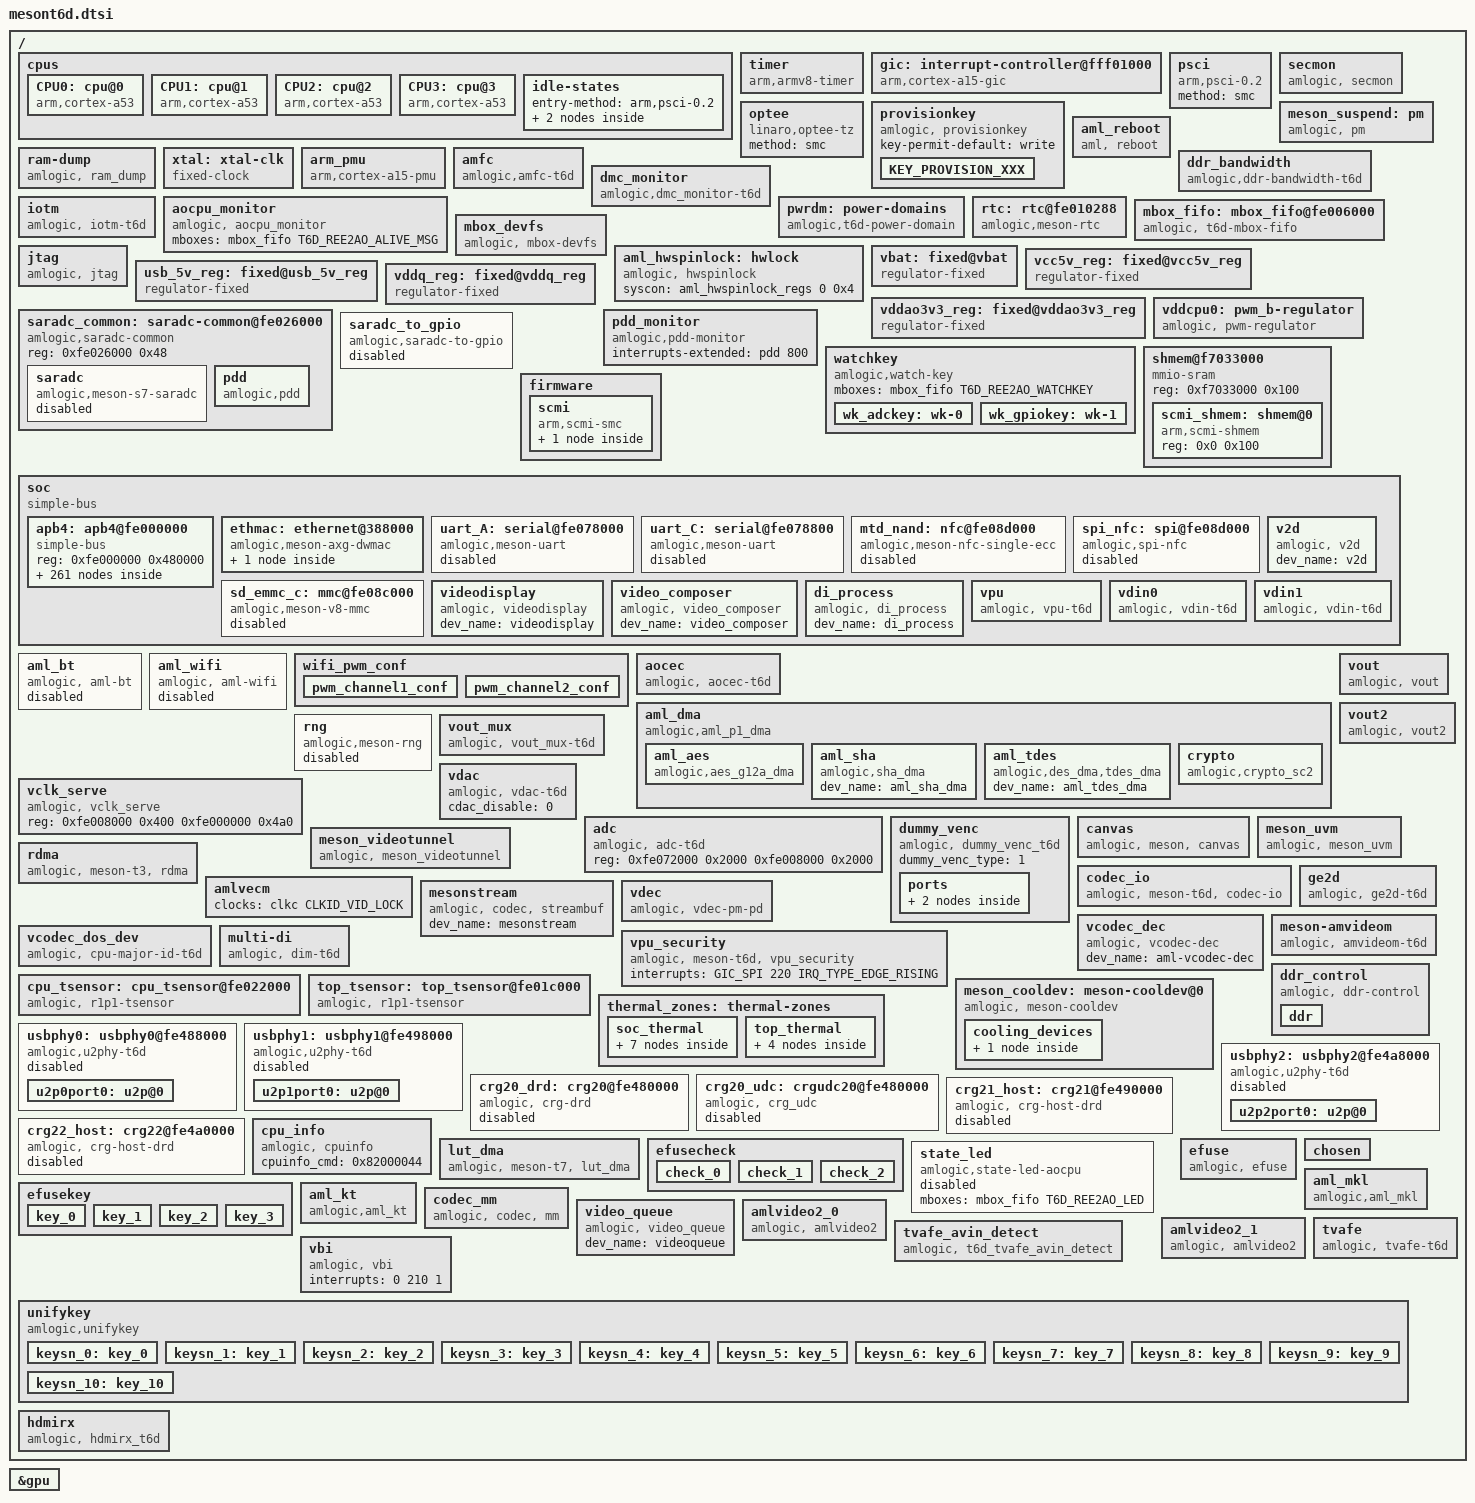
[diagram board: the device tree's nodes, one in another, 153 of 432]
// SPDX-License-Identifier: (GPL-2.0+ OR MIT)
/*
 * Copyright (c) 2021 Amlogic, Inc. All rights reserved.
 */

#include <dt-bindings/interrupt-controller/irq.h>
#include <dt-bindings/interrupt-controller/arm-gic.h>
#include <dt-bindings/reset/amlogic,meson-t6d-reset.h>
#include <dt-bindings/clock/t6d-clkc.h>
#include <dt-bindings/clock/t6d-scmi-clkc.h>
#include <dt-bindings/gpio/gpio.h>
#include <dt-bindings/gpio/meson-t6d-gpio.h>
#include <dt-bindings/power/t6d-pd.h>
#include <dt-bindings/pwm/pwm.h>
#include <dt-bindings/pwm/meson.h>
#include <dt-bindings/input/input.h>
#include <dt-bindings/input/meson_ir.h>
#include <dt-bindings/iio/adc/amlogic-saradc.h>
#include "meson-ir-map.dtsi"
#include "mesong12a-bifrost.dtsi"
#include <dt-bindings/mailbox/t6d-mbox.h>
#include <dt-bindings/thermal/thermal.h>
#include <dt-bindings/thermal/ddr-params.h>
#include <dt-bindings/hwspinlock/amlogic,hwspinlock.h>
#include <dt-bindings/leds/leds-meson.h>

/ {
	cpus:cpus {
		#address-cells = <1>;
		#size-cells = <0>;

		CPU0:cpu@0 {
			device_type = "cpu";
			compatible = "arm,cortex-a53","arm,armv8";
			reg = <0x0>;
			enable-method = "psci";
			cpu-idle-states = <&CPU_SLEEP_0 &SYSTEM_SLEEP_0>;
			dynamic-power-coefficient = <230>;
			#cooling-cells = <2>;
		};

		CPU1:cpu@1{
			device_type = "cpu";
			compatible = "arm,cortex-a53","arm,armv8";
			reg = <0x1>;
			enable-method = "psci";
			cpu-idle-states = <&CPU_SLEEP_0 &SYSTEM_SLEEP_0>;
			dynamic-power-coefficient = <230>;
			#cooling-cells = <2>;
		};

		CPU2:cpu@2 {
			device_type = "cpu";
			compatible = "arm,cortex-a53","arm,armv8";
			reg = <0x2>;
			enable-method = "psci";
			cpu-idle-states = <&CPU_SLEEP_0 &SYSTEM_SLEEP_0>;
			dynamic-power-coefficient = <230>;
			#cooling-cells = <2>;
		};

		CPU3:cpu@3 {
			device_type = "cpu";
			compatible = "arm,cortex-a53","arm,armv8";
			reg = <0x3>;
			enable-method = "psci";
			cpu-idle-states = <&CPU_SLEEP_0 &SYSTEM_SLEEP_0>;
			dynamic-power-coefficient = <230>;
			#cooling-cells = <2>;
		};

		idle-states {
			entry-method = "arm,psci-0.2";
			CPU_SLEEP_0: cpu-sleep-0 {
					compatible = "arm,idle-state";
					arm,psci-suspend-param = <0x0010000>;
					local-timer-stop;
					entry-latency-us = <600>;
					exit-latency-us = <630>;
					min-residency-us = <6140>;
			};
			SYSTEM_SLEEP_0: system-sleep-0 {
					compatible = "arm,idle-state";
					arm,psci-suspend-param = <0x0000000>;
					entry-latency-us = <0x3fffffff>;
					exit-latency-us = <0x40000000>;
					min-residency-us = <0xffffffff>;
			};
		};
	};

	timer {
		compatible = "arm,armv8-timer";
		interrupts = <GIC_PPI 13 0xff08>,
				<GIC_PPI 14 0xff08>,
				<GIC_PPI 11 0xff08>,
				<GIC_PPI 10 0xff08>;
	};

	gic: interrupt-controller@fff01000 {
		compatible = "arm,cortex-a15-gic", "arm,cortex-a9-gic";
		#interrupt-cells = <3>;
		#address-cells = <0>;
		interrupt-controller;
		reg = <0xfff01000 0x1000>,
		      <0xfff02000 0x0100>;
		interrupts = <GIC_PPI 9 0xf04>;
	};

	psci {
		compatible = "arm,psci-0.2";
		method = "smc";
	};

	secmon {
		compatible = "amlogic, secmon";
		memory-region = <&secmon_reserved>;
		in_base_func = <0x82000020>;
		out_base_func = <0x82000021>;
		inout_size_func = <0x8200002a>;
		reserve_mem_size = <0x01300000>;
	};

	optee {
		compatible = "linaro,optee-tz";
		method = "smc";
	};

	provisionkey {
		compatible = "amlogic, provisionkey";
		status = "okay";
		key-permit-default = "write";
		//new key not need add dts if started with KEY_PROVISION_
		KEY_PROVISION_XXX { };
		//test_my_added_keyname { };
	};//End provisionkey

	provisionkey {
		compatible = "amlogic, provisionkey";
		status = "okay";
		key-permit-default = "write";
		//new key not need add dts if started with KEY_PROVISION_
		KEY_PROVISION_XXX { };
		//test_my_added_keyname { };
	};//End provisionkey

	meson_suspend:pm {
		compatible = "amlogic, pm";
		device_name = "aml_pm";
		extend_resume_reason;
		reg = <0xfe010288 0x4>, /*SYSCTRL_STATUS_REG2*/
			<0xfe0102dc 0x4>; /*SYSCTRL_STICKY_REG7*/
		status = "okay";
	};

	aml_reboot {
		compatible = "aml, reboot";
		sys_reset = <0x84000009>;
		sys_poweroff = <0x84000008>;
		dis_nb_cpus_in_shutdown;
		extend_reboot_reason; /* Support up to 128 reboot reasons*/
		reg = <0xfe01037c 0x4>; /* SEC_AO_SEC_SD_CFG15 */
		status = "okay";
	};

	ram-dump {
		compatible = "amlogic, ram_dump";
		status = "okay";
		reg = <0xFE0102D8 4>;
		reg-names = "SYSCTRL_STICKY_REG6";
		store_device = "data";
	};

	xtal: xtal-clk {
		compatible = "fixed-clock";
		clock-frequency = <24000000>;
		clock-output-names = "xtal";
		#clock-cells = <0>;
	};

	arm_pmu {
		compatible = "arm,cortex-a15-pmu";
		private-interrupts;
		interrupts = <GIC_SPI 233 IRQ_TYPE_LEVEL_HIGH>,
				<GIC_SPI 234 IRQ_TYPE_LEVEL_HIGH>,
				<GIC_SPI 235 IRQ_TYPE_LEVEL_HIGH>,
				<GIC_SPI 236 IRQ_TYPE_LEVEL_HIGH>;
	};

	amfc {
		compatible = "amlogic,amfc-t6d";
		status = "okay";
		/* registers and clk, efuse license */
		reg = <0xfe092000 0x200
		       0xFDFFFF6C 0x400
		       0xfe440048 0x400>;
		interrupts = <0 221 IRQ_TYPE_EDGE_RISING
			      0 222 IRQ_TYPE_EDGE_RISING>;
		power-domains = <&pwrdm PDID_T6D_AMFC>;
		interrupt-names = "amfc0", "amfc1";
		clocks = <&clkc CLKID_AMFC>;
		assigned-clocks = <&clkc CLKID_AMFC>;
		assigned-clock-rates = <576000000>;
	};

	ddr_bandwidth {
		compatible = "amlogic,ddr-bandwidth-t6d";
		status = "okay";
		reg = <0xfe036000 0x1000
		       0xfe0368a8 0x4>;
		bus_width_reg = <0xfe036814>;
		interrupts = <0 136 IRQ_TYPE_EDGE_RISING>;
		interrupt-names = "ddr_bandwidth";
	};

	dmc_monitor {
		compatible = "amlogic,dmc_monitor-t6d";
		status = "okay";
		memory-region = <&dmc_reserved>;
		reg = <0xfe036000 0x400>;
		reg_base = <0xfe036000>;
		interrupts = <0 137 IRQ_TYPE_LEVEL_HIGH
			      0 139 IRQ_TYPE_EDGE_RISING>;
	};

	iotm {
		compatible = "amlogic, iotm-t6d";
		status = "okay";
		/* a53_dbg: CSSYS_BASE_ADDR + iotm & coresight */
		reg = <0xfe800000 0x8000>;/* a53_debug */
		exclude-reg = <0xfe807044 0xfe807048>, /* software_write_record of a53_debug */
			      <0xfe078000 0xfe07a000>, /* uart(a-d) */
			      <0xff8100e4 0xff8100e8>, /* vpu amvecm */
			      <0xfe092000 0xfe094000>; /* amfc */
		memory-region = <&debug_reserved>;
		interrupts = <GIC_SPI 128 IRQ_TYPE_LEVEL_HIGH>;
		version = <1>;
	};

	aocpu_monitor {
		compatible = "amlogic, aocpu_monitor";
		status = "okay";
		mboxes = <&mbox_fifo T6D_REE2AO_ALIVE_MSG>;
	};

	pwrdm: power-domains {
		compatible = "amlogic,t6d-power-domain";
		#power-domain-cells = <1>;
		status = "okay";
	};

	rtc: rtc@fe010288 {
		compatible = "amlogic,meson-rtc";
		reg = <0xfe010288 0x4>; //SYSCTRL_STATUS_REG2
		interrupts = <GIC_SPI 3 IRQ_TYPE_EDGE_RISING>;
		status = "okay";
		mboxes = <&mbox_fifo T6D_REE2AO_VRTC>;
		rtc-virtual;
	};

	mbox_fifo: mbox_fifo@fe006000 {
		status = "okay";
		compatible = "amlogic, t6d-mbox-fifo";
		reg = <0xfe006000 0x800>,  /* mbox wr fifo */
		      <0xfe007180 0x80>,   /* mbox set reg */
		      <0xfe007200 0x80>,   /* mbox clr reg */
		      <0xfe007280 0x80>,   /* mbox sts reg */
		      <0xfe007040 0xc0>;   /* mbox irqctrl reg */
		interrupts = <GIC_SPI 248 IRQ_TYPE_EDGE_RISING>;  /* mbox irq top */
		mbox-irqmax = <32>;
		mbox-irqctlr = <0x14>;
		mbox-irqclr = <0x8>;
		mbox-nums = <T6D_MBOX_NUMS>;
		mboxids = <T6D_MBOX_AO2REE>,
			  <T6D_MBOX_REE2AO>;
		#mbox-cells = <1>;
		mbox-wr-same;
		mbox-dests = <MAILBOX_ARM>,
			     <MAILBOX_AOCPU>;
		aocpu-hang-detect;
		aocpu-sts-mboxid = <T6D_AOCPU_STS_CHAN>;
	};

	mbox_devfs {
		status = "okay";
		compatible = "amlogic, mbox-devfs";
		mbox-nums = <2>;
		mbox-names = "ree2aocpu",
			  "aocpu2ree";
		mboxes = <&mbox_fifo T6D_REE2AO_DEV>,
			  <&mbox_fifo T6D_AO2REE_DEV>;
	};

	aml_hwspinlock: hwlock {
		status = "okay";
		compatible = "amlogic, hwspinlock";
		syscon = <&aml_hwspinlock_regs 0 0x4>;
		#hwlock-cells = <1>;
	};

	jtag {
		compatible = "amlogic, jtag";
		status = "okay";
		select = "disable"; /* disable/jtag_a/jtag_b */
		pinctrl-names="jtag_a_pins", "jtag_b_pins";
		pinctrl-0=<&jtag_a_pins>;
		pinctrl-1=<&jtag_b_pins>;
	};

	vbat: fixed@vbat {
		compatible = "regulator-fixed";
		regulator-name = "12V";
		regulator-min-microvolt = <12000000>;
		regulator-max-microvolt = <12000000>;
		regulator-boot-on;
		regulator-always-on;
	};

	vcc5v_reg: fixed@vcc5v_reg {
		vin-supply = <&vbat>;
		compatible = "regulator-fixed";
		regulator-name = "5V/VCC_5V";
		regulator-min-microvolt = <5000000>;
		regulator-max-microvolt = <5000000>;
		gpio = <&gpio GPIO_TEST_N GPIO_ACTIVE_HIGH>;
		startup-delay-us = <7000>;
		enable-active-high;
		regulator-boot-on;
		regulator-always-on;
	};

	usb_5v_reg: fixed@usb_5v_reg {
		compatible = "regulator-fixed";
		vin-supply = <&vcc5v_reg>;
		regulator-name = "USB_5V/OTG_VCC5V,USBBC_PWR";
		regulator-min-microvolt = <5000000>;
		regulator-max-microvolt = <5000000>;
		regulator-boot-on;
		regulator-always-on;
	};

	vddq_reg: fixed@vddq_reg {
		compatible = "regulator-fixed";
		vin-supply = <&vbat>;
		regulator-name = "VDDQ";
		regulator-min-microvolt = <1220000>;
		regulator-max-microvolt = <1220000>;
		pinctrl-names = "default";
		gpio = <&gpio GPIOD_4 GPIO_ACTIVE_HIGH>;
		startup-delay-us = <7000>;
		enable-active-high;
		regulator-boot-on;
		regulator-always-on;
	};

	vddao3v3_reg: fixed@vddao3v3_reg {
		vin-supply = <&vbat>;
		compatible = "regulator-fixed";
		regulator-name = "VDDAO_3.3V";
		regulator-min-microvolt = <3300000>;
		regulator-max-microvolt = <3300000>;
		regulator-boot-on;
		regulator-always-on;
	};

	vddcpu0: pwm_b-regulator {
		compatible = "amlogic, pwm-regulator";
		pwms = <&pwm_b MESON_PWM_0 1512 0>;
		regulator-name = "vddcpu0";
		regulator-min-microvolt = <689000>;
		regulator-max-microvolt = <1049000>;
		regulator-always-on;
		max-duty-cycle = <1512>;
		amlogic,vsel-step = <3>;
		amlogic,usleep-time = <200>;
		/* Voltage Duty-Cycle */
		voltage-table = <1049000 0>,
				<1039000 3>,
				<1029000 6>,
				<1019000 8>,
				<1009000 11>,
				<999000 14>,
				<989000 17>,
				<979000 19>,
				<969000 22>,
				<959000 25>,
				<949000 28>,
				<939000 31>,
				<929000 33>,
				<919000 36>,
				<909000 39>,
				<899000 42>,
				<889000 44>,
				<879000 47>,
				<869000 50>,
				<859000 53>,
				<849000 56>,
				<839000 58>,
				<829000 61>,
				<819000 64>,
				<809000 67>,
				<799000 69>,
				<789000 72>,
				<779000 75>,
				<769000 78>,
				<759000 81>,
				<749000 83>,
				<739000 86>,
				<729000 89>,
				<719000 92>,
				<709000 94>,
				<699000 97>,
				<689000 100>;
		status = "okay";
	};

	saradc_common: saradc-common@fe026000 {
		compatible = "amlogic,saradc-common";
		reg = <0xfe026000 0x48>;

		saradc: saradc {
			compatible = "amlogic,meson-s7-saradc",
				     "amlogic,meson-saradc";
			status = "disabled";
			#io-channel-cells = <1>;
			clocks = <&xtal>,
				 <&clkc CLKID_SYS_SARADC>,
				 <&clkc CLKID_SARADC>,
				 <&clkc CLKID_SARADC_SEL>;
			clock-names = "clkin", "core", "adc_clk", "adc_sel";
			interrupts = <GIC_SPI 181 IRQ_TYPE_EDGE_RISING>;
			watch-key = <&wk_adckey>;
		};

		pdd: pdd {
			compatible = "amlogic,pdd";
			interrupt-controller;
			#interrupt-cells = <1>;
			clock-names = "core";
			clocks = <&clkc CLKID_SYS_SARADC>;
			amlogic,interrupt = <182>;
			amlogic,digital-maps = <0x2c 26>, <0x2c 25>, <0x2c 24>,
					       <0x2c 19>, <0x2c 16>;
			amlogic,analog-maps = <0x2c 9>, <0x2c 3>, <0x2c 1>;
			amlogic,voltage-maps = <400>, <800>, <800>, <1200>;
			status = "okay";
		};
	};

	pdd_monitor {
		compatible = "amlogic,pdd-monitor";
		/* Trigger threshold voltage: 800 mV */
		interrupts-extended = <&pdd 800>;
		status = "okay";
	};

	saradc_to_gpio {
		compatible = "amlogic,saradc-to-gpio";
		io-channels = <&saradc SARADC_CH0>, <&saradc SARADC_CH1>,
			      <&saradc SARADC_CH2>, <&saradc SARADC_CH3>,
			      <&saradc SARADC_CH4>, <&saradc SARADC_CH5>,
			      <&saradc SARADC_CH6>, <&saradc SARADC_CH7>;
		amlogic,threshold = <900 900 900 900 900 900 900 900>;
		status = "disabled";
	};

	watchkey: watchkey {
		compatible = "amlogic,watch-key";
		mboxes = <&mbox_fifo T6D_REE2AO_WATCHKEY>;

		wk_adckey: wk-0 {
			wk-name = "adc-keypad";
			wk-id = <0>;
			wk-type = <EV_KEY>;
			wk-code = <KEY_POWER>;
			/* wk-report-event; */
		};

		wk_gpiokey: wk-1 {
			wk-name = "gpio-keypad";
			wk-id = <1>;
			wk-type = <EV_KEY>;
			wk-code = <KEY_POWER>;
			/* wk-report-event; */
		};
	};

	shmem@f7033000 {
		compatible = "mmio-sram";
		reg = <0xf7033000 0x100>;
		#address-cells = <1>;
		#size-cells = <1>;
		ranges = <0x0 0xf7033000 0x100>;

		scmi_shmem: shmem@0 {
			compatible = "arm,scmi-shmem";
			reg = <0x0 0x100>;
		};
	};

	firmware {
		scmi: scmi {
			compatible = "arm,scmi-smc";
			arm,smc-id = <0x820000c1>;
			shmem = <&scmi_shmem>;
			#address-cells = <1>;
			#size-cells = <0>;

			scmi_clk: protocol@14 {
				reg = <0x14>;
				#clock-cells = <1>;
			};
		};
	};

	soc {
		compatible = "simple-bus";
		#address-cells = <1>;
		#size-cells = <1>;
		ranges;

		apb4: apb4@fe000000 {
			compatible = "simple-bus";
			reg = <0xfe000000 0x480000>;
			#address-cells = <1>;
			#size-cells = <1>;
			ranges = <0x0 0xfe000000 0x480000>;

			reset: reset-controller@2000 {
				compatible = "amlogic,meson-t5m-reset";
				reg = <0x2000 0x98>;
				#reset-cells = <1>;
			};

			watchdog@2100 {
				compatible = "amlogic,meson-a4-wdt";
				status = "okay";
				/* 0:userspace, 1:kernel */
				amlogic,feed_watchdog_mode = <1>;
				reg = <0x2100 0x10>,
				      <0x226c 0x04>;
				interrupts = <GIC_SPI 9 IRQ_TYPE_EDGE_RISING>;
				clocks = <&xtal>;
			};

			clkc: clock-controller {
				compatible = "amlogic,t6d-clkc";
				#clock-cells = <1>;
				reg = <0x0 0x244>,
				      <0x8000 0xe0>;
				reg-names = "basic", "pll";
				clocks = <&xtal>;
				clock-names = "xtal";
				gp0-spread-spectrum = <0>; /* 500,1000,1500...*/
				status = "okay";
			};

			meson_clk_msr@48000 {
				compatible = "amlogic,meson-t6d-clk-measure";
				reg = <0x48000 0x1c>;
				status = "okay";
			};

			uart_B: serial@78400 {
				compatible = "amlogic,meson-uart";
				reg = <0x78400 0x18>;
				interrupts = <0 169 1>;
				status = "disabled";
				clocks = <&xtal>;
				clock-names = "clk_uart";
				xtal_tick_en = <2>;
				fifosize = < 64 >;
				/* 0 not support; 1 support */
				support-sysrq = <1>;
			};

			periphs_pinctrl: pinctrl@4000 {
				compatible = "amlogic,meson-t6d-periphs-pinctrl";
				#address-cells = <1>;
				#size-cells = <1>;
				ranges;

				gpio: bank@4000 {
					reg = <0x4000 0x0058>,
					      <0x40c0 0x030c>;
					reg-names = "mux", "gpio";
					gpio-controller;
					#gpio-cells = <2>;
					gpio-ranges = <&periphs_pinctrl 0 0 129>;
				};
			};

			gpio_intc: interrupt-controller@4080 {
				compatible = "amlogic,meson-t6d-gpio-intc",
					     "amlogic,meson-gpio-intc";
				reg = <0x4080 0x20>;
				interrupt-controller;
				#interrupt-cells = <2>;
				amlogic,channel-interrupts =
					<10 11 12 13 14 15 16 17 18 19 20 21>;
			};

			pinctrl_analog: pinctrl@43cc {
				compatible = "amlogic,meson-t6d-analog-pinctrl";
				#address-cells = <1>;
				#size-cells = <1>;
				ranges;

				gpio_analog: analog-bank@43cc {
					reg = <0x43d4 0x0004>,
					      <0x43cc 0x0008>;
					reg-names = "mux", "gpio";
					gpio-controller;
					#gpio-cells = <2>;
					gpio-ranges = <&pinctrl_analog 0 0 2>;
				};
			};

			spicc0: spi@50000 {
				compatible = "amlogic,meson-a4-spicc-v2";
				reg = <0x50000 0x38>;
				interrupts = <GIC_SPI 183 IRQ_TYPE_LEVEL_HIGH>;
				clocks = <&clkc CLKID_SYS_SPISG>,
					 <&clkc CLKID_SPICC0>;
				clock-names = "sys", "spi";
				#address-cells = <1>;
				#size-cells = <0>;
				status = "disabled";
			};

			spicc1: spi@50100 {
				compatible = "amlogic,meson-a4-spicc-v2";
				reg = <0x50100 0x38>;
				interrupts = <GIC_SPI 184 IRQ_TYPE_LEVEL_HIGH>;
				clocks = <&clkc CLKID_SYS_SPISG>,
					 <&clkc CLKID_SPICC1>;
				clock-names = "sys", "spi";
				#address-cells = <1>;
				#size-cells = <0>;
				status = "disabled";
			};

			pwm_a: pwm@58000 {
				compatible = "amlogic,meson-even-pwm";
				reg = <0x58000 0x24>,
					  <0x180 0x4>;
				#pwm-cells = <3>;
				clocks = <&clkc CLKID_PWM_A_SEL>;
				clock-names = "clkin0";
				status = "disabled";
			};

			pwm_b: pwm@58200 {
				compatible = "amlogic,meson-pwm-tee";
				reg = <0x58200 0x24>;
				#pwm-cells = <3>;
				clocks = <&clkc CLKID_PWM_B>;
				clock-names = "clkin0";
				tee_id = <1>;
				status = "okay";
			};

			pwm_c: pwm@58400 {
				compatible = "amlogic,meson-even-pwm";
				reg = <0x58400 0x24>,
					  <0x184 0x4>;
				#pwm-cells = <3>;
				clocks = <&clkc CLKID_PWM_C_SEL>;
				clock-names = "clkin0";
				status = "disabled";
			};

			pwm_d: pwm@58600 {
				compatible = "amlogic,meson-odd-pwm";
				reg = <0x58600 0x24>,
					  <0x184 0x4>;
				#pwm-cells = <3>;
				clocks = <&clkc CLKID_PWM_D_SEL>;
				clock-names = "clkin0";
				status = "disabled";
			};

			pwm_e: pwm@58800 {
				compatible = "amlogic,meson-even-pwm";
				reg = <0x58800 0x24>,
					  <0x188 0x4>;
				#pwm-cells = <3>;
				clocks = <&clkc CLKID_PWM_E_SEL>;
				clock-names = "clkin0";
				status = "disabled";
			};

			pwm_f: pwm@58a00 {
				compatible = "amlogic,meson-odd-pwm";
				reg = <0x58a00 0x24>,
					  <0x188 0x4>;
				#pwm-cells = <3>;
				clocks = <&clkc CLKID_PWM_F_SEL>;
				clock-names = "clkin0";
				status = "disabled";
			};

			pwm_g: pwm@58c00 {
				compatible = "amlogic,meson-even-pwm";
				reg = <0x58c00 0x24>,
					  <0x18c 0x4>;
				#pwm-cells = <3>;
				clocks = <&clkc CLKID_PWM_G_SEL>;
				clock-names = "clkin0";
				status = "disabled";
			};

			pwm_h: pwm@58e00 {
				compatible = "amlogic,meson-odd-pwm";
				reg = <0x58e00 0x24>,
					  <0x18c 0x4>;
				#pwm-cells = <3>;
				clocks = <&clkc CLKID_PWM_H_SEL>;
				clock-names = "clkin0";
				status = "disabled";
			};

			i2c0: i2c@66000 {
				compatible = "amlogic,meson-i2c";
				reg = <0x66000 0x28>;
				interrupts = <GIC_SPI 160 IRQ_TYPE_EDGE_RISING>;
				#address-cells = <1>;
				#size-cells = <0>;
				clocks = <&clkc CLKID_SYS_I2C_M_WRAPPER>;
				status = "disabled";
			};

			i2c1: i2c@66400 {
				compatible = "amlogic,meson-i2c";
				reg = <0x66400 0x28>;
				interrupts = <GIC_SPI 161 IRQ_TYPE_EDGE_RISING>;
				#address-cells = <1>;
				#size-cells = <0>;
				clocks = <&clkc CLKID_SYS_I2C_M_WRAPPER>;
				status = "disabled";
			};

			i2c2: i2c@66800 {
				compatible = "amlogic,meson-i2c";
				reg = <0x66800 0x28>;
				interrupts = <GIC_SPI 162 IRQ_TYPE_EDGE_RISING>;
				#address-cells = <1>;
				#size-cells = <0>;
				clocks = <&clkc CLKID_SYS_I2C_M_WRAPPER>;
				status = "disabled";
			};

			i2c3: i2c@66c00 {
				compatible = "amlogic,meson-i2c";
				reg = <0x66c00 0x28>;
				interrupts = <GIC_SPI 163 IRQ_TYPE_EDGE_RISING>;
				#address-cells = <1>;
				#size-cells = <0>;
				clocks = <&clkc CLKID_SYS_I2C_M_WRAPPER>;
				status = "disabled";
			};

			dcon_led: dcon_led@74000 {
				compatible = "amlogic,led_unipolar_ctrl";
				reg = <0x74000 0x88>;
				interrupts = <GIC_SPI 30 IRQ_TYPE_EDGE_RISING>;
				led-mode = <LED_MESON_RGB>;
				led_number = <2>;
				status = "disabled";
			};

			ir: ir@fe084000 {
				compatible = "amlogic, meson-ir";
				reg = <0x84080 0xA4>,
					<0x84000 0x58>;
				status = "disabled";
				protocol = <REMOTE_TYPE_NEC>;
				interrupts = <GIC_SPI 22 IRQ_TYPE_EDGE_RISING>;
				map = <&custom_maps>;
				wakeup_map = <&ir_wakeup_key>;
				mboxes = <&mbox_fifo T6D_REE2AO_IR>;
				max_frame_time = <200>;
			};

			ir1: ir1@fe084180 {
				compatible = "amlogic, meson-ir";
				reg = <0x84200 0xA4>,
					<0x84180 0x58>;
				status = "disabled";
				protocol = <REMOTE_TYPE_NEC>;
				interrupts = <GIC_SPI 31 IRQ_TYPE_EDGE_RISING>;
				map = <&custom_maps>;
				max_frame_time = <200>;
			};

			irblaster: meson-irblaster@fe08410c {
				compatible = "amlogic, meson_irblaster";
				status = "disabled";
				reg = <0x8410c 0x10>;
				#irblaster-cells = <2>;
				interrupts = <GIC_SPI 23 IRQ_TYPE_EDGE_RISING>;
			};

			eth_phy: mdio-multiplexer@380000 {
				compatible = "amlogic,g12a-mdio-mux";
				reg = <0x380000 0xa4>;

				clocks = <&clkc CLKID_SYS_ETHPHY>,
					<&xtal>,
					<&clkc CLKID_MPLL_50M>;
				clock-names = "pclk", "clkin0", "clkin1";
				mdio-parent-bus = <&mdio0>;
				#address-cells = <1>;
				#size-cells = <0>;
				enet_type = <5>;
				phy_pll_mode = <2>;
				phy_mode = <7>;
				tx_amp_src = <0xFE010330>;

				ext_mdio: mdio@0 {
					reg = <0>;
					#address-cells = <1>;
					#size-cells = <0>;
				};

				int_mdio: mdio@1 {
					reg = <1>;
					#address-cells = <1>;
					#size-cells = <0>;

					internal_ephy: ethernet_phy@8 {
						compatible = "ethernet-phy-id0180.3301",
							     "ethernet-phy-ieee802.3-c22";
						interrupts = <GIC_SPI 73 IRQ_TYPE_LEVEL_HIGH>;
						reg = <8>;
						max-speed = <100>;
					};
				};
			};

			aml_hwspinlock_regs: syscon@e2c0 {
				compatible = "syscon";
				reg = <0xe2c0 0x20>;
				status = "okay";
			};
		};

		ethmac: ethernet@388000 {
			compatible = "amlogic,meson-axg-dwmac",
				     "snps,dwmac-4.00";
			reg = <0xfe388000 0x12ec>,
			      <0xfe384000 0x8>;
			interrupts = <GIC_SPI 74 IRQ_TYPE_LEVEL_HIGH>;
			interrupt-names = "macirq";
			clocks = <&clkc CLKID_SYS_ETHPHY>,
				 <&clkc CLKID_FCLK_DIV2>,
				 <&clkc CLKID_MPLL_50M>;
			clock-names = "stmmaceth", "clkin0", "clkin1";
			rx-fifo-depth = <4096>;
			tx-fifo-depth = <2048>;
			/*1:inphy; 2:exphy;*/
			internal_phy = <1>;
			analog_version = <1>;
			mboxes = <&mbox_fifo T6D_REE2AO_ETH>;

			mdio0: mdio {
				#address-cells = <1>;
				#size-cells = <0>;
				compatible = "snps,dwmac-mdio";
			};
		};

		uart_A: serial@fe078000 {
			compatible = "amlogic,meson-uart";
			reg = <0xfe078000 0x18>;
			interrupts = <0 168 1>;
			status = "disabled";
			clocks = <&xtal
				&clkc CLKID_SYS_UART_WRAPPER>;
			clock-names = "clk_uart",
				"clk_gate";
			xtal_tick_en = <2>;
			fifosize = < 64 >;
			pinctrl-names = "default";
			pinctrl-0 = <&a_uart_pins1>;
		};

		uart_C: serial@fe078800 {
			compatible = "amlogic,meson-uart";
			reg = <0xfe078800 0x18>;
			interrupts = <0 170 1>;
			status = "disabled";
			clocks = <&xtal
				&clkc CLKID_SYS_UART_WRAPPER>;
			clock-names = "clk_uart",
				"clk_gate";
			xtal_tick_en = <2>;
			fifosize = < 64 >;
			pinctrl-names = "default";
			pinctrl-0 = <&c_uart_pins1>;
		};

		mtd_nand: nfc@fe08d000 {
			compatible = "amlogic,meson-nfc-single-ecc";
			status = "disabled";
			reg = <0xfe08d000 0x200>;
			interrupts = <GIC_SPI 175 IRQ_TYPE_EDGE_RISING>;
			/* share gate of sysclk with EMMC_C */
			clocks = <&clkc CLKID_SYS_SD_EMMC_C>,
					<&clkc CLKID_FCLK_DIV2>;
			clock-names = "gate", "fdiv2pll";
			nand_clk_ctrl = <0xfe08c000>;
			spi_cfg = <0xfe08d040>;
			common_pageinfo = <1>;
		};

		spi_nfc: spi@fe08d000 {
			compatible = "amlogic,spi-nfc";
			status = "disabled";
			reg = <0xfe08d000 0x200>,
				  <0xfe08c000 0xc>,
				  <0xfe010180 0x4>;
			clocks = <&clkc CLKID_SYS_SD_EMMC_C>,
					<&clkc CLKID_FCLK_DIV2>;
			clock-names = "gate", "fdiv2pll";
			nand_clk_ctrl = <0xfe08c000>;
			#address-cells = <1>;
			#size-cells = <0>;
		};

		sd_emmc_c: mmc@fe08c000 {
			compatible = "amlogic,meson-v8-mmc";
			reg = <0xfe08c000 0x1000>,
				<0xfe000168 0x4>,
				<0xfe004000 0x4>;
			interrupts = <GIC_SPI 178 IRQ_TYPE_EDGE_RISING>;
			status = "disabled";
			clocks = <&clkc CLKID_SYS_SD_EMMC_C>,
				<&clkc CLKID_SD_EMMC_C_SEL>,
				<&clkc CLKID_SD_EMMC_C>,
				<&xtal>,
				<&clkc CLKID_GP0_PLL>,
				<&clkc CLKID_GP0_PLL>;
			clock-names = "core", "mux0", "mux1",
					"clkin0", "clkin1", "clkin2";

			card_type = <1>;
			src_clk_rate = <1152000000>;
			mmc_debug_flag;
			ignore_desc_busy;
			tx_delay = <15>;
			cap-mmc-crypto;
			no-sd;
			no-sdio;
			resets = <&reset RESET_SD_EMMC_C>;
		};

		v2d {
			compatible = "amlogic, v2d";
			dev_name = "v2d";
			status = "okay";
		};

		videodisplay {
			compatible = "amlogic, videodisplay";
			dev_name = "videodisplay";
			status = "okay";
		};

		video_composer {
			compatible = "amlogic, video_composer";
			dev_name = "video_composer";
			status = "okay";
		};

		di_process {
			compatible = "amlogic, di_process";
			dev_name = "di_process";
			status = "okay";
		};

		vpu: vpu {
			compatible = "amlogic, vpu-t6d";
			status = "okay";
			reg =   <0xfe000000 0x100    /* clk */
				0xfe00c000 0x70     /* pwrctrl */
				0xff800000 0xf000>; /* vcbus */
			clocks = <&clkc CLKID_VAPB_0>,
				<&clkc CLKID_VAPB_1>,
				<&clkc CLKID_VAPB>,
				<&clkc CLKID_VPU_0>,
				<&clkc CLKID_VPU_1>,
				<&clkc CLKID_VPU>;
			clock-names =   "vapb_clk0",
					"vapb_clk1",
					"vapb_clk",
					"vpu_clk0",
					"vpu_clk1",
					"vpu_clk";
			clk_level = <6>;
			/* 0: 24.0M  1: 100.0M    2: 166.7M    3: 200.0M    4: 250.0M */
			/* 5: 333.3M    6: 400.0M    7: 500.0M    8: 666.7M */
		};

		/*if you want to use vdin just modify status to "ok"*/
		vdin0: vdin0 {/*common define*/
			status = "okay";
			compatible = "amlogic, vdin-t6d";
			dev_name = "vdin0";
			/*status = "disabled";*/
			/*memory-region = <&vdin0_cma_reserved>;*/
			reserve-iomap = "true";
			flag_cma = <0x10101>;/*1:share with codec_mm;2:cma alone*/
			/*MByte, if 10bit disable: 64M(YUV422),
			 *if 10bit enable: 64*1.5 = 96M(YUV422)
			 *if support 4K2K-YUV444-10bit-WR:3840*2160*4*4 ~= 128M
			 *if support 4K2K-YUV422-10bit-wr:3840*2160*3*4 ~= 96M
			 *if support 4K2K-YUV422-8BIT-WR:3840*2160*2*4 ~= 64M
			 *if support 1080p-YUV422-8BIT-WR:1920*1080*2*4 ~= 16M
			 * onebuffer:
			 * worst case:(4096*2160*3 + 2M(afbce issue)) = 27.5M
			 * dw:960x540x3 = 1.5M
			 * total size:(27.5+1.5)x buffernumber
			 */
			/*cma_size = <174>;*/
			/*frame_buff_num = <6>;*/
			interrupts = <0 210 1 /* vdin0 vsync */
					/*0 214 1*/ /* vdin1 write down*/
					/*0 206 1*/ /* vpu crash */
					/*0 213 1*/>; /* vdin0 write down*/
			interrupt-names = "vsync_int"
					/*"mif2_meta_wr_done_int"*/
					/*"vpu_crash_int",*/
					/*"write_done_int"*/;
			rdma-irq = <2>;
			clocks = <&clkc CLKID_FCLK_DIV5>, <&clkc CLKID_VDIN_MEAS>;
				clock-names = "fclk_div5", "cts_vdin_meas_clk";
			vdin_id = <0>;
			/*vdin write mem color depth support:
			 * bit0:support 8bit
			 * bit1:support 9bit
			 * bit2:support 10bit
			 * bit3:support 12bit
			 * bit4:support yuv422 10bit full pack mode (from txl new add)
			 * bit5:force yuv422 to yuv444 malloc (for vdin0 debug)
			 * bit8:use 8bit  at 4k_50/60hz_10bit
			 * bit9:use 10bit at 4k_50/60hz_10bit
			 * bit10: support 10bit when double write
			 */
			tv_bit_mode = <0x235>;
			/* afbce_bit_mode: (amlogic frame buff compression encoder)
			 * bit0 -- enable afbce
			 * bit1 -- enable afbce compression-lossy
			 * bit4 -- afbce for 4k
			 * bit5 -- afbce for 1080p
			 * bit6 -- afbce for 720p
			 * bit7 -- afbce for smaller resolution
			 */
			afbce_bit_mode = <0x0>;
			chk_wr_done_en;
			/* urgent_en; */
			secure_cfg;
			double_write_en;
			vdin_function_sel = <0x20001>;
			/* vdin v4l2 */
			v4l_support_en = <0>;
			v4l_vd_num = <70>;
			/* v4l2 capability */
			driver   = "vdinvideo";
			card     = "mesont3";
			bus_info = "vdin0 v4l2";
			version  = <0x20220120>;
			/* fe_ports refer to tvin.h */
			fe_ports = <0x00001001   /* CVBS1 */
				0x00004000   /* HDMI0 */
				0x00004001   /* HDMI1 */
				0x00004002>; /* HDMI2 */
			/* vdin v4l2 end */
		};

		vdin1: vdin1 {/*common define*/
			status = "okay";
			compatible = "amlogic, vdin-t6d";
			dev_name = "vdin1";
			/*status = "disabled";*/
			reserve-iomap = "true";
			/*memory-region = <&vdin1_cma_reserved>;*/
			flag_cma = <0>;/*1:share with codec_mm;0:cma alone*/
			interrupts = <0 212 1>;
			interrupt-names = "vsync_int"/*, "vpu_crash_int",*/
					/*"write_done_int"*/;
			rdma-irq = <4>;
			vdin_id = <1>;
			clocks = <&clkc CLKID_FCLK_DIV5>, <&clkc CLKID_VDIN_MEAS>;
				clock-names = "fclk_div5", "cts_vdin_meas_clk";
			tv_bit_mode = <0x15>;
			chk_wr_done_en;
			/* vdin v4l2 */
			v4l_support_en = <0>;
			v4l_vd_num = <71>;
			/* v4l2 capability */
			driver   = "vdinvideo";
			card     = "mesont3";
			bus_info = "vdin1 v4l2";
			version  = <0x20220120>;
			/* fe_ports refer to tvin.h */
			fe_ports = <0x0000a002   /* WB0_VD1 */
				0x0000a003   /* WB0_VD2 */
				0x0000a004   /* WB0_OSD1 */
				0x0000a005   /* WB0_OSD2 */
				0x0000a006   /* WB0_VPP */
				0x0000a007   /* WB0_VDIN_BIST */
				0x0000a008   /* WB0_POST_BLEND */
				0x0000a001>; /* VIDEO */
			/* vdin v4l2 end */
		};
	};

	aml_bt: aml_bt {
		compatible = "amlogic, aml-bt";
		status = "disabled";
	};

	aml_wifi: aml_wifi {
		compatible = "amlogic, aml-wifi";
		status = "disabled";
		irq_trigger_type = "GPIO_IRQ_LOW";
		//dhd_static_buf;
		pwm_config = <&wifi_pwm_conf>;
	};

	wifi_pwm_conf:wifi_pwm_conf{
		pwm_channel1_conf {
			// pwms = <&pwm_ef 0 30550 0>;
			duty-cycle = <15270>;
			times = <8>;
		};
		pwm_channel2_conf {
			// pwms = <&pwm_ef 2 30500 0>;
			duty-cycle = <15250>;
			times = <12>;
		};
	};

	aocec: aocec {
		compatible = "amlogic, aocec-t6d";
		dev_name = "aocec";
		status = "okay";
		vendor_name = "Amlogic"; /* Max Chars: 8     */
		/* Refer to the following URL at:
		 * http://standards.ieee.org/develop/regauth/oui/oui.txt
		 */
		vendor_id = <0x000000>;
		product_desc = "T6D"; /* Max Chars: 16    */
		cec_osd_string = "AML_TV"; /* Max Chars: 14    */
		cec_version = <5>;/*5:1.4;6:2.0*/
		port_num = <3>;
		output = <0>;
		cec_sel = <1>;/*1:use one ip, 2:use 2 ip*/
		ee_cec; /*use cec a or b*/
		arc_port_mask = <0x1>;
		interrupts = <GIC_SPI 180 IRQ_TYPE_EDGE_RISING>;/*0:snps*/
		interrupt-names = "hdmi_aocecb";
		pinctrl-names = "default","hdmitx_aocecb","cec_pin_sleep";
		pinctrl-0=<&cec_b>;
		pinctrl-1=<&cec_b>;
		pinctrl-2=<&cec_b>;
		clocks = <&clkc CLKID_CECB_32K_CLKOUT>;
		clock-names = "cecb_clk";
		reg = <0xfe044000 0x2000
		       0xfe010000 0x2000
		       0xfe000000 0x2000
		       0xfe004000 0x2000>;
		reg-names = "ao","periphs","clock","pad_reg";
		mbox-names = "mbox_cec";
		mboxes = <&mbox_fifo T6D_REE2AO_AOCEC>;
	};

	aml_dma {
		compatible = "amlogic,aml_p1_dma";
		reg = <0xfe440400 0x48>;
		interrupts = <0 24 1>;
		status = "okay";

		aml_aes {
			compatible = "amlogic,aes_g12a_dma";
			dev_name = "aml_aes_dma";
			iv_swap = /bits/ 8 <0x0>;
			status = "okay";
		};

		aml_sha {
			compatible = "amlogic,sha_dma";
			dev_name = "aml_sha_dma";
			status = "okay";
		};

		aml_tdes {
			compatible = "amlogic,des_dma,tdes_dma";
			dev_name = "aml_tdes_dma";
			status = "okay";
		};

		crypto {
			compatible = "amlogic,crypto_sc2";
			dev_name = "aml_crypto_dev";
			status = "okay";
			thread = /bits/ 8 <0x5>;
			interrupts = <0 29 1>;
		};
	};

	rng {
		compatible = "amlogic,meson-rng";
		status = "disabled"; /* disabled as default */
		#address-cells = <1>;
		#size-cells = <1>;
		reg = <0xfe440788 0x0c>;
		quality = /bits/ 16 <1000>;
		version = <2>;
	};

	vclk_serve: vclk_serve {
		compatible = "amlogic, vclk_serve";
		status = "okay";
		reg = <0xfe008000 0x400    /* ana reg */
			0xfe000000 0x4a0>; /* clk reg */
	};

	vout_mux: vout_mux {
		compatible = "amlogic, vout_mux-t6d";
		status = "okay";
		clocks = <&clkc CLKID_FCLK_DIV5>, <&clkc CLKID_VDIN_MEAS>;
		clock-names = "fclk_div5", "vdin_meas_clk";
	};

	vout: vout {
		compatible = "amlogic, vout";
		status = "okay";
		interrupts = <GIC_SPI 194 IRQ_TYPE_EDGE_RISING>;
		interrupt-names = "vsync";
		vs_meas=<0>;
	};

	vdac: vdac {
		compatible = "amlogic, vdac-t6d";
		status = "okay";
		cdac_disable = <0>;
	};

	adc: adc {
		compatible = "amlogic, adc-t6d";
		status = "okay";
		reg = <0xfe072000 0x2000/* afe reg base */
			0xfe008000 0x2000/* hiu base */
		>;
	};

	vout2: vout2 {
		compatible = "amlogic, vout2";
		status = "okay";
	};

	dummy_venc: dummy_venc {
		compatible = "amlogic, dummy_venc_t6d";
		status = "okay";
		dummy_venc_type = <1>; /* 0 dummyl，1 dummyp，2 dummyi */
		ports {
			port {
				#address-cells = <1>;
				#size-cells = <0>;
				dummyp_to_drm: endpoint@0 {
					reg = <0>;
					remote-endpoint = <0>;
				};
			};
		};
	};

	canvas: canvas {
		compatible = "amlogic, meson, canvas";
		status = "okay";
	};

	meson_uvm {
		compatible = "amlogic, meson_uvm";
		status = "okay";
	};

	meson_videotunnel{
		compatible = "amlogic, meson_videotunnel";
		status = "okay";
	};

	rdma {
		compatible = "amlogic, meson-t3, rdma";
		status = "okay";
		interrupts = <GIC_SPI 215 IRQ_TYPE_EDGE_RISING>;
		interrupt-names = "rdma";
		/* after sc2 */
		reset-names = "rdma";
		resets = <&reset RESET_RDMA>;
		rdma_table_page_count = <16>;
	};

	codec_io: codec_io {
		compatible = "amlogic, meson-t6d, codec-io";
		status = "okay";
		#address-cells=<1>;
		#size-cells=<1>;
		ranges;
		reg =	<0xfe002000 0x2000>,
			<0xfe320000 0x10000>,
			<0x0 0x0>,
			<0x0 0x00>,
			<0xff800000 0x40000>,
			<0xfe036000 0x2000>,
			<0x0 0x0>,
			<0xfe0a8000 0x2000>;
		reg-names = "cbus",
			    "dosbus",
			    "hiubus",
			    "aobus",
			    "vcbus",
			    "dmcbus",
			    "efusebus",
				"nocbus";
	};

	ge2d {
		compatible = "amlogic, ge2d-t6d";
		status = "okay";
		interrupts = <GIC_SPI 217 IRQ_TYPE_EDGE_RISING>;
		interrupt-names = "ge2d";
		clocks = <&clkc CLKID_VAPB>,
			<&clkc CLKID_SYS_GE2D>,
			<&clkc CLKID_GE2D_GATE>;
		clock-names = "clk_vapb_0",
			"clk_ge2d",
			"clk_ge2d_gate";
		reg = <0xff840000 0x100>;
		power-domains = <&pwrdm PDID_T6D_GE2D>;
	};

	amlvecm: amlvecm {
		clocks = <&clkc CLKID_VID_LOCK>;
		clock-names = "cts_vid_lock_clk";
	};

	mesonstream {
		compatible = "amlogic, codec, streambuf";
		dev_name = "mesonstream";
		status = "okay";
	};

	vdec {
		compatible = "amlogic, vdec-pm-pd";
		dev_name = "vdec.0";
		status = "okay";
		interrupts = <0 3 1
			0 23 1
			0 32 1
			0 91 1
			0 92 1
			0 93 1
			0 72 1>;
		interrupt-names = "vsync",
			"demux",
			"parser",
			"mailbox_0",
			"mailbox_1",
			"mailbox_2",
			"parser_b";
		power-domains = <&pwrdm PDID_T6D_DOS_HEVC>,
			<&pwrdm PDID_T6D_DOS_HEVC>;
		power-domain-names = "pwrc-hevc",
			"pwrc-dummy";
	};

	vcodec_dec {
		compatible = "amlogic, vcodec-dec";
		dev_name = "aml-vcodec-dec";
		status = "okay";
	};

	vcodec_dos_dev: vcodec_dos_dev {
		compatible = "amlogic, cpu-major-id-t6d";
		dev_name = "vcodec_dos_dev";
		status = "okay";
		reg = <0xfe320000 0x10000>,
			<0xfe036000 0x2000>,
			<0xfe010000 0x2000>;
		reg-names = "dosbus",
			"dmcbus",
			"sysctrl";
		clocks = <&clkc CLKID_SYS_DOS
			&clkc CLKID_HEVCB>;
		clock-names = "vdec",
			"clk_hevc_mux";
		assigned-clock-parents = <&clkc CLKID_HEVCB_0>;
		assigned-clocks = <&clkc CLKID_HEVCB>;
	};

	meson-amvideom {
		compatible = "amlogic, amvideom-t6d";
		dev_name = "amvideom";
		status = "okay";
		vpp0_hold_line = <7>;
		interrupts = <GIC_SPI 194 IRQ_TYPE_EDGE_RISING>;
		interrupt-names = "vsync";
	};

	vpu_security {
		compatible = "amlogic, meson-t6d, vpu_security";
		status = "okay";
		interrupts = <GIC_SPI 220 IRQ_TYPE_EDGE_RISING>;
		interrupt-names = "vpu_security";
	};

	multi-di {
		compatible = "amlogic, dim-t6d";
		status = "okay";
		/* 0:use reserved; 1:use cma; 2:use cma as reserved */
		flag_cma = <4>;	//<1>;
		//memory-region = <&di_reserved>;
		//memory-region = <&di_cma_reserved>;
		interrupts = <0 203 1
				0 202 1>;
		interrupt-names = "pre_irq", "post_irq";
		clocks = <&clkc CLKID_VPU_CLKB>,
			<&clkc CLKID_VPU>;
		clock-names = "vpu_clkb",
			"vpu_mux";
		clock-range = <334 400>;
		/* buffer-size = <3621952>;(yuv422 8bit) */
		buffer-size = <4074560>;/*yuv422 fullpack*/
		/* reserve-iomap = "true"; */
		/* if enable nr10bit, set nr10bit-support to 1 */
		post-wr-support = <0>;
		nr10bit-support = <1>;
		nrds-enable = <1>;
		pps-enable = <1>;
		en_4k = <0>;
		keep_dec_vf = <0>;
		po_fmt = <0>;
		post_nub = <11>;
		alloc_sct = <0>;
		hf = <0>;
		dct = <0>;
		sub_v = <0>;//sub version
		afbce_loss_en = <0>;//t5w loss mode enable for DI output
		prelink_en = <1>;
		ponly_mode = <1>;
		t5db_afbcd_en = <1>;
		postlink_en = <1>;
		/***************************************************
		 * t5w t3 support 4k ,same with t7 ,no canvas,
		 * post_nub---default is 11
		 *            (T7/T3/SC2/S4 new path)
		 *            post 11*5222400 = 56M,local 7*4075520 = 28m
		 * flag_cma---0: use reserved; 1:use cma;
		 *            2:use cma as reserved 4:use codec mem
		 * en_4k :en_4k---0: not support 4K;  1: enable 4K
		 *                2: dynamic: vdin: 4k enable,
		 *                   other source 4k disable
		 *                8: when 4k,
		 *                   output with a resolution is below 1080p
		 * keep_dec_vf---0:not keep; 1: keep dec vf for p;
		 *               2: dynamic keep dec vf for p,other is disable
		 * po_fmt---1: NV21/8;  2: nv12/8;  3: AFBC 422/10BIT;
		 *          4: dynamic(4K AFBC,10/422);
		 *          6: dynamic(from decoder 4K source,
		 *             out is AFBC,10/420),
		 *             other is 422/10BIT
		 * bypass_mem---0:nr not bypass; 1: nr bypass;
		 *              2: when 4k input ,nr is bypass;
		 *              3: bypass nr for 4k,but not from vdin;
		 * alloc_sct---0:not support; bit 0: for 4k; bit 1: for 1080p
		 * hf---0:not enable; 1: enable
		 * dct---0:not enable; 1: enable 1 ch; 2: enable 2 ch
		 * sub_v---0:major; 1: sub
		 * afbce_loss_en---1:check the loss flag in vf and set for di,0:disable
		 ***************************************************/
	};

	cpu_tsensor: cpu_tsensor@fe022000 {
		compatible = "amlogic, r1p1-tsensor";
		status = "okay";
		reg = <0xfe022000 0x50>;
		tsensor_id = <1>;
		cal_type = <0x11>;
		cal_coeff = <296 396 2907 8739>;
		rtemp = <120000>;
		interrupts = <GIC_SPI 83 IRQ_TYPE_LEVEL_HIGH>;
		clocks = <&clkc CLKID_TS_CLK>;
		clock-names = "ts_comp";
		#thermal-sensor-cells = <1>;
		reset-names = "ts_rst";
		resets = <&reset RESET_TS_CPU>;
		cust_governor = "power_allocator";
	};

	top_tsensor: top_tsensor@fe01c000 {
		compatible = "amlogic, r1p1-tsensor";
		status = "okay";
		reg = <0xfe01c000 0x50>;
		tsensor_id = <2>;
		cal_type = <0x11>;
		cal_coeff = <296 396 2907 8739>;
		rtemp = <120000>;
		interrupts = <GIC_SPI 85 IRQ_TYPE_LEVEL_HIGH>;
		clocks = <&clkc CLKID_TS_CLK>;
		clock-names = "ts_comp";
		#thermal-sensor-cells = <1>;
		reset-names = "ts_rst";
		resets = <&reset RESET_TS_TOP>;
	};

	meson_cooldev: meson-cooldev@0 {
		status = "okay";
		compatible = "amlogic, meson-cooldev";
		cooling_devices {
			gpufreq_cool {
				dyn_coeff = <358>;
				node_name = "bifrost";
				device_type = "gpufreq";
			};
		};
	};/*meson cooling devices end*/

	thermal_zones: thermal-zones {
		soc_thermal: soc_thermal {
			polling-delay = <1000>;
			polling-delay-passive = <100>;
			sustainable-power = <900>;
			thermal-sensors = <&cpu_tsensor 0>;
			trips {
				cpu_switch_on: trip-point@0 {
					temperature = <95000>;
					hysteresis = <5000>;
					type = "passive";
				};
				cpu_control: trip-point@1 {
					temperature = <105000>;
					hysteresis = <5000>;
					type = "passive";
				};
				cpu_critical: trip-point@2 {
					temperature = <115000>;
					hysteresis = <1000>;
					type = "critical";
				};
			};
			cooling-maps {
				cpufreq_cooling_map {
					trip = <&cpu_control>;
					cooling-device = <&CPU0 0 8>;
					contribution = <1024>;
				};
				gpufreq_cooling_map {
					trip = <&cpu_control>;
					cooling-device = <&gpu 0 3>;
					contribution = <1024>;
				};
			};
		};

		top_thermal: top_thermal {
			polling-delay = <2000>;
			polling-delay-passive = <1000>;
			sustainable-power = <900>;
			thermal-sensors = <&top_tsensor 1>;
			trips {
				top_switch_on: trip-point@0 {
					temperature = <95000>;
					hysteresis = <5000>;
					type = "passive";
				};
				top_control: trip-point@1 {
					temperature = <105000>;
					hysteresis = <5000>;
					type = "passive";
				};
				top_critical: trip-point@2 {
					temperature = <115000>;
					hysteresis = <1000>;
					type = "critical";
				};
			};
		};
	};/*thermal zone end*/

	ddr_control: ddr_control {
		compatible = "amlogic, ddr-control";
		reg = <0xfe0368a8 0x4>;
		reg-names = "freq-addr";
		freq-mask = <0 16>;
		version = "v3";
		status = "okay";
		ddr {
			condition-type = <DDR_THERMAL>;
			zone-name = "soc_thermal";
			caddr = <0xfe0364b4>,
				<0xfe0365b4>;
			caddr-mask = <0 16>,
				     <0 16>;
			cstep-val = <75000 80000 85000 90000>,
				    <95000 100000 105000 110000>;
			caddr-val = <7800 3900>,
				    <6240 3120>,
				    <4875 2438>,
				    <4875 2438>,
				    <3900 1950>,
				    <3120 1560>,
				    <2437 1219>,
				    <1950 975>;
		};
	};

	usbphy0: usbphy0@fe488000 {
		compatible = "amlogic,u2phy-t6d";
		#address-cells = <1>;
		#size-cells = <1>;
		//ranges = <0 0 0 0x1000>;
		status = "disabled";
		u2p0port0: u2p@0 {
			#phy-cells = <0>;
			port-speed = <0x0>; /* 0~2: HS HSP SS */
			reg = <0xfe488000 0x100
					0xfe002000 0x100
					0xfe010330 0x4
					0xfe48c000 0x60>;
			reset-level = <0x40>;
			phy-reset-level-bits = <6>;
			phy-reg-reset-bit = <0>;
			usb-reset-bit = <1>;
			pll-settings = <0x0
							0x0
							0x0
							0x0
							0x7>;
			clocks = <&clkc CLKID_SYS_USB_U2DRD>,
						<&clkc CLKID_USB2_48M_CLK>,
						<&clkc CLKID_USB2_48M_PRE>;

			clock-names = "crg_general",
						"clk_soc_u2drd_48m",
						"clk_soc_u2drd_48m_pre";
			/* 48m soc-digital cfg. */
			assigned-clocks = <&clkc CLKID_USB2_48M_CLK>;
			assigned-clock-parents = <&clkc CLKID_USB2_48M_PRE>;
			/* 48m soc-analog cfg. */
			//assigned-clocks = <&clkc CLKID_USB2_48M_CLK_TMP_SEL>,
			//					<&clkc CLKID_USB2_48M_CLK>;
			//assigned-clock-parents = <&clkc CLKID_USB_PLL>,
			//					<&clkc CLKID_USB2_48M_CLK_TMP>;
			//assigned-clock-rates = <0>, <48000000>;
			phy-otg;
			interrupts = <0 130 IRQ_TYPE_EDGE_RISING>;
		};
	};

	usbphy1: usbphy1@fe498000 {
		compatible = "amlogic,u2phy-t6d";
		#address-cells = <1>;
		#size-cells = <1>;
		//ranges = <0 0 0 0x1000>;
		status = "disabled";
		u2p1port0: u2p@0 {
			#phy-cells = <0>;
			port-speed = <0x0>; /* 0~2: HS HSP SS */
			reg = <0xfe498000 0x100
					0xfe002000 0x100
					0xfe010330 0x4
					0xfe49c000 0x60>;
			reset-level = <0x40>;
			phy-reset-level-bits = <7>;
			phy-reg-reset-bit = <2>;
			usb-reset-bit = <3>;
			pll-settings = <0x0
							0x0
							0x0
							0x0
							0x7>;
			clocks = <&clkc CLKID_SYS_USB_U2H>;
			clock-names = "crg_general";
		};
	};

	usbphy2: usbphy2@fe4a8000 {
		compatible = "amlogic,u2phy-t6d";
		#address-cells = <1>;
		#size-cells = <1>;
		//ranges = <0 0 0 0x1000>;
		status = "disabled";
		u2p2port0: u2p@0 {
			#phy-cells = <0>;
			port-speed = <0x0>; /* 0~2: HS HSP SS */
			reg = <0xfe4a8000 0x100
					0xfe002000 0x100
					0xfe010330 0x4
					0xfe4ac000 0x60>;
			reset-level = <0x40>;
			phy-reset-level-bits = <8>;
			phy-reg-reset-bit = <4>;
			usb-reset-bit = <5>;
			pll-settings = <0x0
							0x0
							0x0
							0x0
							0x7>;
			clocks = <&clkc CLKID_SYS_USB_U22H>,
						<&clkc CLKID_USB2_48M_CLK>,
						<&clkc CLKID_USB2_48M_PRE>;
			clock-names = "crg_general",
						"clk_soc_u2drd_48m",
						"clk_soc_u2drd_48m_pre";
			/* 48m soc-digital cfg. */
			assigned-clocks = <&clkc CLKID_USB2_48M_CLK>;
			assigned-clock-parents = <&clkc CLKID_USB2_48M_PRE>;
			/* 48m soc-analog cfg. */
			//assigned-clocks = <&clkc CLKID_USB2_48M_CLK_TMP_SEL>,
			//					<&clkc CLKID_USB2_48M_CLK>;
			//assigned-clock-parents = <&clkc CLKID_USB_PLL>,
			//					<&clkc CLKID_USB2_48M_CLK_TMP>;
			//assigned-clock-rates = <0>, <48000000>;
			sw-hsp;
		};
	};

	crg20_drd: crg20@fe480000 {
		compatible = "amlogic, crg-drd";
		status = "disabled";
		reg = <0xfe480000 0x8000>;
		interrupts = <0 131 IRQ_TYPE_EDGE_RISING>;
		phys = <&u2p0port0>;
		phy-names = "usb2-phy";
		clocks = <&clkc CLKID_SYS_USB_U2DRD>;
		clock-names = "crg_general";
		rd-outstanding-tune = <0x8>;
		in-nak-rty = <0x5>;
		reset-names = "udrd";
		resets = <&reset RESET_USB0>;
	};

	crg20_udc: crgudc20@fe480000 {
		compatible = "amlogic, crg_udc";
		status = "disable";
		controller-type = <1>; /* 1: aml phy 4: m31 phy */
		reg = <0xfe480000 0x8000>;
		interrupts = <0 131 IRQ_TYPE_EDGE_RISING>;
		port-speed = <3>; /* 0~3: unknown, low, full, high */
		phys = <&u2p0port0>;
		clocks = <&clkc CLKID_SYS_USB_U2DRD>;
		clock-names = "usb_general";
		version = <1>; /* forbid vbus detect */
		reset-names = "udrd";
		resets = <&reset RESET_USB0>;
	};

	crg21_host: crg21@fe490000 {
		compatible = "amlogic, crg-host-drd";
		status = "disabled";
		reg = <0xfe490000 0x8000>;
		interrupts = <0 79 IRQ_TYPE_EDGE_RISING>;
		phys = <&u2p1port0>;
		phy-names = "usb2-phy";
		clocks = <&clkc CLKID_SYS_USB_U2H>;
		clock-names = "crg_general";
		rd-outstanding-tune = <0x8>;
		in-nak-rty = <0x5>;
		reset-names = "udrd";
		resets = <&reset RESET_USB1>;
	};

	crg22_host: crg22@fe4a0000 {
		compatible = "amlogic, crg-host-drd";
		status = "disabled";
		reg = <0xfe4a0000 0x8000>;
		interrupts = <0 55 IRQ_TYPE_EDGE_RISING>;
		phys = <&u2p2port0>;
		phy-names = "usb2-phy";
		clocks = <&clkc CLKID_SYS_USB_U22H>;
		clock-names = "crg_general";
		rd-outstanding-tune = <0x8>;
		in-nak-rty = <0x5>;
		reset-names = "udrd";
		resets = <&reset RESET_USB2>;
	};

	cpu_info {
		compatible = "amlogic, cpuinfo";
		cpuinfo_cmd = <0x82000044>;
	};

	lut_dma:lut_dma {
		compatible = "amlogic, meson-t7, lut_dma";
		status = "okay";
	};

	efusecheck: efusecheck{
		maincmd = <0x8200003E>;
		checknum = <3>;
		check0 = <&check_0>;
		check1 = <&check_1>;
		check2 = <&check_2>;
		check_0:check_0{
			checkname = "dgpk1";
			subcmd = <0x1000>;
		};
		check_1:check_1{
			checkname = "dgpk2";
			subcmd = <0x1001>;
		};
		check_2:check_2{
			checkname = "aud_id";
			subcmd = <0x1002>;
		};
	};

	efuse: efuse{
		compatible = "amlogic, efuse";
		reg=<0xfe440040 0x4>;
		secureboot_mask = <0x00000c00>;
		read_cmd = <0x82000030>;
		write_cmd = <0x82000031>;
		get_max_cmd = <0x82000033>;
		mem_in_base_cmd = <0x82000020>;
		mem_out_base_cmd = <0x82000021>;
		efuse_pattern_size = <0x600>;
		efuse_obj_cmd_status = <0x1>;
		efuse_cali_item_read = <0x1>;
		key = <&efusekey>;
		check = <&efusecheck>;
		clock-names = "efuse_clk";
		status = "okay";
	};

	efusekey:efusekey{
		keynum = <4>;
		key0 = <&key_0>;
		key1 = <&key_1>;
		key2 = <&key_2>;
		key3 = <&key_3>;
		key_0:key_0{
			keyname = "mac";
			offset = <0>;
			size = <6>;
		};
		key_1:key_1{
			keyname = "mac_bt";
			offset = <6>;
			size = <6>;
		};
		key_2:key_2{
			keyname = "mac_wifi";
			offset = <12>;
			size = <6>;
		};
		key_3:key_3{
			keyname = "usid";
			offset = <18>;
			size = <16>;
		};
	};

	state_led: state_led {
		compatible = "amlogic,state-led-aocpu";
		mboxes = <&mbox_fifo T6D_REE2AO_LED>;
		status = "disabled";
	};

	chosen {
		bootargs = "usbcore.autosuspend=-1 dm_mod.reserved_bio_based_ios=8";
	};

	aml_mkl {
		compatible = "amlogic,aml_mkl";
		reg = <0xfe440200 0xf0>;
		kl_type = <1>;
		kl_vid_type = <1>;
		kl_offset = <0x80 0x88 0x8c 0x90>;
		status = "okay";
	};

	aml_kt {
		compatible = "amlogic,aml_kt";
		reg = <0xfe440500 0xa0>;
		kt_offset = <0x80 0x88 0x8c 0x90 0x94 0x98 0x9c>;
		kt_cap = <0x2407 0x6bf 0 16 0 32>;
		kt_reserved = <0>;
		kt_host_key_max_len = <32>;
		status = "okay";
	};

	codec_mm: codec_mm {
		compatible = "amlogic, codec, mm";
		memory-region = <&codec_mm_cma &secure_vdec_reserved>;
		dev_name = "codec_mm";
		status = "okay";
		/* secure memory controller para <switch  align_2n> */
		secure_ctrl_para = <1 16>;
		/*
		 * scatter_alloc_mode: the mode of scatter memory allocation
		 * 0: default mode, alloc from system and cma
		 * 1: only alloc from system
		 * 2: only alloc from cma
		 */
		scatter_alloc_mode = <1>;
	};

	video_queue {
		compatible = "amlogic, video_queue";
		dev_name = "videoqueue";
		status = "okay";
	};

	amlvideo2_0: amlvideo2_0 {
		compatible = "amlogic, amlvideo2";
		dev_name = "amlvideo2";
		status = "okay";
		amlvideo2_id = <0>;
		cma_mode = <1>;
	};

	amlvideo2_1: amlvideo2_1 {
		compatible = "amlogic, amlvideo2";
		dev_name = "amlvideo2";
		status = "okay";
		amlvideo2_id = <1>;
		cma_mode = <1>;
	};

	tvafe_avin_detect {
		compatible = "amlogic, t6d_tvafe_avin_detect";
		status = "okay";
		device_mask = <1>;/*bit0:ch1;bit1:ch2*/
		reg = <0xfe00a000 0x400>; /* cvbs irq base */
		interrupts = <0 173 1>;
	};

	tvafe: tvafe {
		compatible = "amlogic, tvafe-t6d";
		/*memory-region = <&tvafe_cma_reserved>;*/
		status = "okay";
		flag_cma = <1>;/*1:share with codec_mm;0:cma alone*/
		cma_size = <5>;/*MByte*/
		reg = <0xfe072000 0x2000/*tvafe reg base*/
			0xfe008000 0x2000>; /*ana reg base*/
		reserve-iomap = "true";
		tvafe_id = <0>;
		//pinctrl-names = "default";
		/*!!particular sequence, no more and no less!!!*/
		tvafe_pin_mux = <
				3 /* TVAFE_CVBS_IN2, CVBS_IN0 = 0 */
				1 /* TVAFE_CVBS_IN0, CVBS_IN1 */
				2 /* TVAFE_CVBS_IN1, CVBS_IN2 */
				4 /* TVAFE_CVBS_IN3, CVBS_IN3 */
		>;
		clocks = <&clkc CLKID_CDAC_CLK>;
		clock-names = "vdac_clk_gate";
		cutwindow_val_h = <0 0 0 0 8>; /* level 0~4 */
		cutwindow_val_v = <4 8 14 16 24>;  /* level 0~4 */
		horizontal_dir0 = <148 148 148 148 148>;
		horizontal_dir1 = <148 168 166 160 148>;
		horizontal_stp0 = <0 0 0 0 0>;
		horizontal_stp1 = <0 0 0 0 0>;
		macrovision = <1>;
	};

	vbi {
		compatible = "amlogic, vbi";
		status = "okay";
		interrupts = <0 210 1>;
		interrupt-names = "vsync_int";
	};

	unifykey {
		compatible = "amlogic,unifykey";
		status = "okay";

		unifykey-num = <11>;
		unifykey-index-0 = <&keysn_0>;
		unifykey-index-1 = <&keysn_1>;
		unifykey-index-2 = <&keysn_2>;
		unifykey-index-3 = <&keysn_3>;
		unifykey-index-4 = <&keysn_4>;
		unifykey-index-5 = <&keysn_5>;
		unifykey-index-6 = <&keysn_6>;
		unifykey-index-7 = <&keysn_7>;
		unifykey-index-8 = <&keysn_8>;
		unifykey-index-9 = <&keysn_9>;
		unifykey-index-10 = <&keysn_10>;

		keysn_0: key_0{
			key-name = "usid";
			key-device = "normal";
			key-permit = "read","write","del";
		};
		keysn_1:key_1{
			key-name = "mac";
			key-device  = "normal";
			key-permit = "read","write","del";
		};
		keysn_2:key_2{
			key-name = "secure_boot_set";
			key-device = "efuse";
			key-permit = "write";
		};
		keysn_3:key_3{
			key-name = "mac_bt";
			key-device = "normal";
			key-permit = "read","write","del";
			key-type  = "mac";
		};
		keysn_4:key_4{
			key-name = "mac_wifi";
			key-device = "normal";
			key-permit = "read","write","del";
			key-type  = "mac";
		};
		keysn_5:key_5{
			key-name = "hdcp2_rx";
			key-device = "normal";
			key-permit = "read","write","del";
		};
		keysn_6:key_6{
			key-name = "deviceid";
			key-device = "normal";
			key-permit = "read","write","del";
		};
		keysn_7:key_7{
			key-name = "lcd_tcon_spi";
			key-device = "normal";
			key-permit = "read","write","del";
		};
		keysn_8:key_8{
			key-name = "oemkey";
			key-device = "normal";
			key-permit = "read","write","del";
		};
		keysn_9:key_9{
			key-name = "model_name";
			key-device = "normal";
			key-permit = "read","write","del";
		};
		keysn_10:key_10{
			key-name = "diag_state";
			key-device = "normal";
			key-permit = "read","write","del";
		};
	}; /* End unifykey */

	hdmirx: hdmirx {
		compatible = "amlogic, hdmirx_t6d";
		#address-cells=<1>;
		#size-cells=<1>;
		/*memory-region = <&hdmirx_emp_cma_reserved>;*/
		status = "okay";
		pinctrl-names = "hdmirx_pins";
		pinctrl-0 = <&hdmirx_a_mux &hdmirx_b_mux
			&hdmirx_c_mux>;
		repeat = <0>;
		/*power-domains = <&pwrdm PDIP_T6D_VPU_HDMI>;*/
		interrupts = <0 57 IRQ_TYPE_LEVEL_HIGH>;
		clocks =<&clkc CLKID_HDMIRX_CFG>,
			<&clkc CLKID_HDMIRX_ACR>,
			<&clkc CLKID_HDMIRX_METER>,
			<&clkc CLKID_HDMIRX_2M>,
			<&clkc CLKID_HDMIRX_5M>,
			<&clkc CLKID_HDMIRX_HDCP>,
			<&xtal>,
			<&clkc CLKID_FCLK_DIV4>,
			<&clkc CLKID_FCLK_DIV5>;
		clock-names = "hdmirx_cfg_clk",
				"cts_hdmirx_acr_ref_clk",
				"cts_hdmirx_meter_clk",
				"cts_hdmirx_2m_clk",
				"cts_hdmirx_5m_clk",
				"cts_hdmirx_hdcp2x_eclk",
				"xtal",
				"fclk_div4",
				"fclk_div5";
		//power-domains = <&pwrdm 2>;
		hdmirx_id = <0>;
		en_4k_2_2k = <0>;
		hpd_low_cec_off = <1>;
		arc_port = <0>;
		/* for 2.2R:0x8, for 5.1R:0x6 */
		term_lvl = <0x6>;
		vrr_range_dynamic_update_en = <1>;
		/* bit4: enable feature, bit3~0: port number */
		disable_port = <0x0>;
		/* MAP_ADDR_MODULE_CBUS */
		/* MAP_ADDR_MODULE_HIU */
		/* MAP_ADDR_MODULE_HDMIRX_CAPB3 */
		/* MAP_ADDR_MODULE_SEC_AHB */
		/* MAP_ADDR_MODULE_SEC_AHB2 */
		/* MAP_ADDR_MODULE_APB4 */
		/* MAP_ADDR_MODULE_TOP */
		/* MAP_ADDR_MODULE_CLK_CTRL */
		/* MAP_ADDR_MODULE_ANA_CTRL */
		reg = < 0x0 0x0
			0x0 0x0
			0x0 0x0
			0x0 0x0
			0x0 0x0
			0x0 0x0
			0xfe398000 0x18000
			0xfe000000 0x2ffff
			0xfe008000 0x334>;
	};
};

&periphs_pinctrl {
	emmc_pins: emmc {
		mux-0 {
			groups = "emmc_d0",
				 "emmc_d1",
				 "emmc_d2",
				 "emmc_d3",
				 "emmc_d4",
				 "emmc_d5",
				 "emmc_d6",
				 "emmc_d7",
				 "emmc_cmd";
			function = "emmc";
			bias-pull-up;
			drive-strength-microamp = <3000>;
		};

		mux-1 {
			groups = "emmc_clk";
			function = "emmc";
			bias-disable;
			drive-strength-microamp = <3000>;
		};
	};

	emmc_ds_pins: emmc-ds {
		mux {
			groups = "emmc_ds";
			function = "emmc";
			bias-pull-down;
			drive-strength-microamp = <3000>;
		};
	};

	emmc_clk_gate_pins: emmc_clk_gate {
		mux {
			groups = "GPIOB_8";
			function = "gpio_periphs";
			bias-pull-down;
			drive-strength-microamp = <3000>;
		};
	};

	/* sdemmc portB */
	sd_clk_cmd_pins:sd_clk_cmd_pins {
		mux {
			groups = "sdcard_cmd_c";
			function = "sdcard";
			bias-pull-up;
			drive-strength-microamp = <4000>;
		};
		mux1 {
			groups = "sdcard_clk_c";
			function = "sdcard";
			bias-pull-up;
			drive-strength-microamp = <4000>;
		};
	};

	sd_all_pins:sd_all_pins {
		mux {
			groups = "sdcard_d0_c",
				   "sdcard_d1_c",
				   "sdcard_d2_c",
				   "sdcard_d3_c",
				   "sdcard_cmd_c";
			function = "sdcard";
			bias-pull-up;
			drive-strength-microamp = <4000>;
		};
		mux1 {
			groups = "sdcard_clk_c";
			function = "sdcard";
			bias-pull-up;
			drive-strength-microamp = <4000>;
		};
	};

	sd_clk_gate_pins: sd_clk_gate {
		mux {
			groups = "GPIOC_4";
			function = "gpio_periphs";
			bias-pull-down;
			drive-strength-microamp = <4000>;
		};
	};

	sd_all_pd_pins:sd_all_pd_pins {
		mux {
			groups = "GPIOC_0",
				   "GPIOC_1",
				   "GPIOC_2",
				   "GPIOC_3",
				   "GPIOC_4",
				   "GPIOC_5";
			function = "gpio_periphs";
			bias-pull-down;
			output-low;
		};
	};

	sd_1bit_pins:sd_1bit_pins {
		mux {
			groups = "sdcard_d0_c",
					"sdcard_cmd_c";
			function = "sdcard";
			bias-pull-up;
			drive-strength-microamp = <4000>;
		};
		mux1 {
			groups = "sdcard_clk_c";
			function = "sdcard";
			bias-pull-up;
			drive-strength-microamp = <4000>;
		};
	};

	hdmirx_a_mux:hdmirx_a_mux {
		mux {
			groups = "hdmirx_hpd_a",
				"hdmirx_5vdet_a",
				"hdmirx_sda_a",
				"hdmirx_scl_a";
			function = "hdmirx";
		};
	};

	hdmirx_b_mux:hdmirx_b_mux {
		mux {
			groups = "hdmirx_hpd_b",
				"hdmirx_5vdet_b",
				"hdmirx_sda_b",
				"hdmirx_scl_b";
			function = "hdmirx";
		};
	};

	hdmirx_c_mux:hdmirx_c_mux {
		mux {
			groups = "hdmirx_hpd_c",
				"hdmirx_5vdet_c",
				"hdmirx_sda_c",
				"hdmirx_scl_c";
			function = "hdmirx";
		};
	};

	cec_b: cec_b {
		mux {
			groups = "cec";
			function = "cec";
		};
	};

	irblaster_pins1:irblaster_pin1 {
		mux {
			groups = "remote_out_b";
			function = "remote_out";
		};
	};

	irblaster_pins2:irblaster_pin2 {
		mux {
			groups = "remote_out_d1";
			function = "remote_out";
		};
	};

	irblaster_pins3:irblaster_pin3 {
		mux {
			groups = "remote_out_d9";
			function = "remote_out";
		};
	};

	irblaster_pins4:irblaster_pin4 {
		mux {
			groups = "remote_out_p6";
			function = "remote_out";
		};
	};

	irblaster_pins5:irblaster_pin5 {
		mux {
			groups = "remote_out_p9";
			function = "remote_out";
		};
	};

	pwm_a_pins1: pwm_a_pins1 {
		mux {
			groups = "pwm_a_e0";
			function = "pwm_a";
		};
	};

	pwm_a_pins2: pwm_a_pins2 {
		mux {
			groups = "pwm_a_d11";
			function = "pwm_a";
		};
	};

	pwm_b_pins1: pwm_b_pins1 {
		mux {
			groups = "pwm_b_e1";
			function = "pwm_b";
		};
	};

	pwm_b_pins2: pwm_b_pins2 {
		mux {
			groups = "pwm_b_z4";
			function = "pwm_b";
		};
	};

	pwm_c_pins1: pwm_c_pins1 {
		mux {
			groups = "pwm_c_d5";
			function = "pwm_c";
		};
	};

	pwm_c_pins2: pwm_c_pins2 {
		mux {
			groups = "pwm_c_d7";
			function = "pwm_c";
		};
	};

	pwm_c_pins3: pwm_c_pins3 {
		mux {
			groups = "pwm_c_d11";
			function = "pwm_c";
		};
	};

	pwm_d_pins1: pwm_d_pins1 {
		mux {
			groups = "pwm_d_z5";
			function = "pwm_d";
		};
	};

	pwm_d_pins2: pwm_d_pins2 {
		mux {
			groups = "pwm_d_m1";
			function = "pwm_d";
		};
	};

	pwm_d_pins3: pwm_d_pins3 {
		mux {
			groups = "pwm_d_m23";
			function = "pwm_d";
		};
	};

	pwm_d_pins4: pwm_d_pins4 {
		mux {
			groups = "pwm_d_d9";
			function = "pwm_d";
		};
	};

	pwm_d_pins5: pwm_d_pins5 {
		mux {
			groups = "pwm_d_h5";
			function = "pwm_d";
		};
	};

	pwm_d_pins6: pwm_d_pins6 {
		mux {
			groups = "pwm_d_h12";
			function = "pwm_d";
		};
	};

	pwm_e_pins1: pwm_e_pins1 {
		mux {
			groups = "pwm_e_z6";
			function = "pwm_e";
		};
	};

	pwm_e_pins2: pwm_e_pins2 {
		mux {
			groups = "pwm_e_h13";
			function = "pwm_e";
		};
	};

	pwm_e_pins3: pwm_e_pins3 {
		mux {
			groups = "pwm_e_m24";
			function = "pwm_e";
		};
	};

	pwm_e_pins4: pwm_e_pins4 {
		mux {
			groups = "pwm_e_d10";
			function = "pwm_e";
		};
	};

	pwm_e_pins5: pwm_e_pins5 {
		mux {
			groups = "pwm_e_e2";
			function = "pwm_e";
		};
	};

	pwm_f_pins1: pwm_f_pins1 {
		mux {
			groups = "pwm_f_c10";
			function = "pwm_f";
		};
	};

	pwm_f_pins2: pwm_f_pins2 {
		mux {
			groups = "pwm_f_d6";
			function = "pwm_f";
		};
	};

	pwm_f_pins3: pwm_f_pins3 {
		mux {
			groups = "pwm_f_m26";
			function = "pwm_f";
		};
	};

	pwm_f_pins4: pwm_f_pins4 {
		mux {
			groups = "pwm_f_m10";
			function = "pwm_f";
		};
	};

	pwm_f_pins5: pwm_f_pins5 {
		mux {
			groups = "pwm_f_d12";
			function = "pwm_f";
		};
	};

	pwm_g_pins1: pwm_g_pins1 {
		mux {
			groups = "pwm_g_z12";
			function = "pwm_g";
		};
	};

	pwm_g_pins2: pwm_g_pins2 {
		mux {
			groups = "pwm_g_z19";
			function = "pwm_g";
		};
	};

	pwm_g_pins3: pwm_g_pins3 {
		mux {
			groups = "pwm_g_m8";
			function = "pwm_g";
		};
	};

	pwm_h_pins1: pwm_h_pins1 {
		mux {
			groups = "pwm_h_d6";
			function = "pwm_h";
		};
	};

	pwm_h_pins2: pwm_h_pins2 {
		mux {
			groups = "pwm_h_z13";
			function = "pwm_h";
		};
	};

	pwm_h_pins3: pwm_h_pins3 {
		mux {
			groups = "pwm_h_m9";
			function = "pwm_h";
		};
	};

	pwm_c_hiz_pins: pwm_c_hiz_pins {
		mux {
			groups = "pwm_c_hiz";
			function = "pwm_c_hiz";
		};
	};

	pwm_d_hiz_pins: pwm_d_hiz_pins {
		mux {
			groups = "pwm_d_hiz";
			function = "pwm_d_hiz";
		};
	};

	lcd_vbyone_a_pins: lcd_vbyone_a_pin {
		mux {
			groups = "vx1_a_lockn","vx1_a_htpdn";
			function = "vx1";
		};
	};

	lcd_vbyone_a_off_pins: lcd_vbyone_a_off_pin {
		mux {
			groups = "GPIOH_0","GPIOH_1";
			function = "gpio_periphs";
			input-enable;
		};
	};

	lcd_tcon_p2p_pins: lcd_tcon_p2p_pin {
		mux {
			groups = "tcon_1","tcon_2","tcon_3",
				"tcon_4","tcon_5","tcon_6",
				"tcon_lock";
			function = "tcon";
		};
	};

	lcd_tcon_p2p_usit_pins: lcd_tcon_p2p_usit_pin {
		mux {
			groups = "tcon_1","tcon_2","tcon_3",
				"tcon_4","tcon_5","tcon_6",
				"tcon_sfc_h0";
			function = "tcon";
		};
	};

	lcd_tcon_p2p_off_pins: lcd_tcon_p2p_off_pin {
		mux {
			groups = "GPIOH_1","GPIOH_2","GPIOH_3",
				"GPIOH_4","GPIOH_5","GPIOH_6",
				"GPIOH_0";
				function = "gpio_periphs";
			input-enable;
		};
	};

	lcd_tcon_mlvds_pins: lcd_tcon_mlvds_pin {
		mux {
			groups = "tcon_0","tcon_1","tcon_2","tcon_3",
				"tcon_4","tcon_5","tcon_6","tcon_8",
				"tcon_9","tcon_10","tcon_11";
			function = "tcon";
		};
	};

	lcd_tcon_mlvds_off_pins: lcd_tcon_mlvds_off_pin {
		mux {
			groups = "GPIOH_0","GPIOH_1","GPIOH_2","GPIOH_3",
				"GPIOH_4","GPIOH_5","GPIOH_6","GPIOH_8",
				"GPIOH_9","GPIOH_10","GPIOH_11";
			function = "gpio_periphs";
			input-enable;
		};
	};

	remote_pins: remote_pin {
		mux {
			groups = "ir_in_a";
			function = "ir";
			bias-disable;
		};
	};

	remote_b_pins: remote_b_pin {
		mux {
			groups = "ir_in_b_z18";
			function = "ir";
			bias-disable;
		};
	};

	i2c0_pins1:i2c0_pins1 {
		mux {
			groups = "i2c0_scl",
				"i2c0_sda";
			function = "i2c0";
			drive-strength-microamp = <3000>;
			bias-disable;
		};
	};

	i2c0_pins1_sleep:i2c0_pins1_sleep {
		mux {
			groups = "GPIOZ_4",
				"GPIOZ_5";
			function = "gpio_periphs";
			input-enable;
		};
	};

	i2c1_pins1:i2c1_pins1 {
		mux {
			groups = "i2c1_scl_d2",
				"i2c1_sda_d3";
			function = "i2c1";
			drive-strength-microamp = <3000>;
			bias-disable;
		};
	};

	i2c1_pins1_sleep:i2c1_pins1_sleep {
		mux {
			groups = "GPIOD_2",
				"GPIOD_3";
			function = "gpio_periphs";
			input-enable;
		};
	};

	i2c1_pins2:i2c1_pins2 {
		mux {
			groups = "i2c1_scl_d14",
				"i2c1_sda_d13";
			function = "i2c1";
			drive-strength-microamp = <3000>;
			bias-disable;
		};
	};

	i2c1_pins2_sleep:i2c1_pins2_sleep {
		mux {
			groups = "GPIOD_14",
				"GPIOD_13";
			function = "gpio_periphs";
			input-enable;
		};
	};

	i2c2_pins1:i2c2_pins1 {
		mux {
			groups = "i2c2_sda_e1",
				"i2c2_scl_e0";
			function = "i2c2";
			drive-strength-microamp = <3000>;
			bias-disable;
		};
	};

	i2c2_pins1_sleep:i2c2_pins1_sleep {
		mux {
			groups = "GPIOE_1",
				"GPIOE_0";
			function = "gpio_periphs";
			input-enable;
		};
	};

	i2c2_pins2:i2c2_pins2 {
		mux {
			groups = "i2c2_sda_h21",
				"i2c2_scl_h20";
			function = "i2c2";
			drive-strength-microamp = <3000>;
			bias-disable;
		};
	};

	i2c2_pins2_sleep:i2c2_pins2_sleep {
		mux {
			groups = "GPIOH_21",
				"GPIOH_20";
			function = "gpio_periphs";
			input-enable;
		};
	};

	i2c2_pins3:i2c2_pins3 {
		mux {
			groups = "i2c2_sda_h11",
				"i2c2_scl_h10";
			function = "i2c2";
			drive-strength-microamp = <3000>;
			bias-disable;
		};
	};

	i2c2_pins3_sleep:i2c2_pins3_sleep {
		mux {
			groups = "GPIOH_11",
				"GPIOH_10";
			function = "gpio_periphs";
			input-enable;
		};
	};

	i2c2_pins4:i2c2_pins4 {
		mux {
			groups = "i2c2_sda_h3",
				"i2c2_scl_h2";
			function = "i2c2";
			drive-strength-microamp = <3000>;
			bias-disable;
		};
	};

	i2c2_pins4_sleep:i2c2_pins4_sleep {
		mux {
			groups = "GPIOH_3",
				"GPIOH_2";
			function = "gpio_periphs";
			input-enable;
		};
	};

	i2c2_pins5:i2c2_pins5 {
		mux {
			groups = "i2c2_sda_m26",
				"i2c2_scl_m25";
			function = "i2c2";
			drive-strength-microamp = <3000>;
			bias-disable;
		};
	};

	i2c2_pins5_sleep:i2c2_pins5_sleep {
		mux {
			groups = "GPIOM_26",
				"GPIOM_25";
			function = "gpio_periphs";
			input-enable;
		};
	};

	i2c3_pins1:i2c3_pins1 {
		mux {
			groups = "i2c3_sda_d7",
				"i2c3_scl_d6";
			function = "i2c3";
			drive-strength-microamp = <3000>;
			bias-disable;
		};
	};

	i2c3_pins1_sleep:i2c3_pins1_sleep {
		mux {
			groups = "GPIOD_7",
				"GPIOD_6";
			function = "gpio_periphs";
			input-enable;
		};
	};

	i2c3_pins2:i2c3_pins2 {
		mux {
			groups = "i2c3_sda_c1",
				"i2c3_scl_c0";
			function = "i2c3";
			drive-strength-microamp = <3000>;
			bias-disable;
		};
	};

	i2c3_pins2_sleep:i2c3_pins2_sleep {
		mux {
			groups = "GPIOC_1",
				"GPIOC_0";
			function = "gpio_periphs";
			input-enable;
		};
	};

	i2c3_pins3:i2c3_pins3 {
		mux {
			groups = "i2c3_scl_m27",
				"i2c3_sda_m28";
			function = "i2c3";
			drive-strength-microamp = <3000>;
			bias-disable;
		};
	};

	i2c3_pins3_sleep:i2c3_pins3_sleep {
		mux {
			groups = "GPIOM_27",
				"GPIOM_28";
			function = "gpio_periphs";
			input-enable;
		};
	};

	dcon_led_pins1:dcon_led_pins1 {
		mux {
			groups = "dcon_led_d7";
			function = "dcon_led";
		};
	};

	dcon_led_pins2:dcon_led_pins2 {
		mux {
			groups = "dcon_led_c10";
			function = "dcon_led";
		};
	};

	dcon_led_pins3:dcon_led_pins3 {
		mux {
			groups = "dcon_led_z18";
			function = "dcon_led";
		};
	};

	dcon_led_pins4:dcon_led_pins4 {
		mux {
			groups = "dcon_led_d8";
			function = "dcon_led";
		};
	};

	dcon_led_pins5:dcon_led_pins5 {
		mux {
			groups = "dcon_led_d9";
			function = "dcon_led";
		};
	};

	a_uart_pins1:a_uart1 {
		mux {
			groups = "uart_a_tx_c6",
				 "uart_a_rx_c7",
				 "uart_a_cts_c8",
				 "uart_a_rts_c9";
			function = "uart_a";
			drive-strength-microamp = <3000>;
			bias-pull-up;
		};
	};

	a_uart_pins2:a_uart2 {
		mux {
			groups = "uart_a_tx_z0",
				 "uart_a_rx_z1",
				 "uart_a_cts_z2",
				 "uart_a_rts_z3";
			function = "uart_a";
			drive-strength-microamp = <3000>;
			bias-pull-up;
		};
	};

	a_uart_pins3:a_uart3 {
		mux {
			groups = "uart_a_tx_m0",
				 "uart_a_rx_m1",
				 "uart_a_cts_m2",
				 "uart_a_rts_m3";
			function = "uart_a";
			drive-strength-microamp = <3000>;
			bias-pull-up;
		};
	};

	c_uart_pins1:c_uart1 {
		mux {
			groups = "uart_c_tx_d6",
				 "uart_c_rx_d7";
			function = "uart_c";
			drive-strength-microamp = <3000>;
			bias-pull-up;
		};
	};

	c_uart_pins2:c_uart2 {
		mux {
			groups = "uart_c_tx_h2",
				"uart_c_rx_h3",
				"uart_c_cts_h4",
				"uart_c_rts_h5";
			function = "uart_c";
			drive-strength-microamp = <3000>;
			bias-pull-up;
		};
	};

	c_uart_pins3:c_uart3 {
		mux {
			groups = "uart_c_tx_m19",
				"uart_c_rx_m20",
				"uart_c_cts_m21",
				"uart_c_rts_m22";
			function = "uart_c";
			drive-strength-microamp = <3000>;
			bias-pull-up;
		};
	};

	jtag_a_pins: jtag_a_pin {
		mux {
			groups = "jtag_a_clk_d6",
				 "jtag_a_tms_d7",
				 "jtag_a_tdi_d8",
				 "jtag_a_tdo_d9";
			function = "jtag_a";
		};

		mux-unused {
			groups = "GPIOW_2",
				 "GPIOW_3",
				 "GPIOW_6",
				 "GPIOW_7";
			function = "gpio_periphs";
		};
	};

	jtag_b_pins: jtag_b_pin {
		mux {
			groups = "jtag_a_clk_w2",
				 "jtag_a_tms_w3",
				 "jtag_a_tdi_w6",
				 "jtag_a_tdo_w7";
			function = "jtag_a";
		};

		mux-unused {
			groups = "GPIOD_6",
				 "GPIOD_7",
				 "GPIOD_8",
				 "GPIOD_9";
			function = "gpio_periphs";
		};
	};

	atvdemod_agc_pins: atvdemod_agc_pins {
		mux {
			groups = "atv_if_agc_z6";
			function = "atv_if_agc";
		};
	};

	dtvdemod_if_agc_pins: dtvdemod_if_agc_pins {
		mux {
			groups = "dtv_if_agc_z6";
			function = "dtv";
		};
	};

	dtvdemod_rf_agc_pins: dtvdemod_rf_agc_pins {
		mux {
			groups = "dtv_rf_agc_z6";
			function = "dtv";
		};
	};

	dvb_p_ts1_pins: dvb_p_ts1_pins {
		mux {
			groups = "tsin_b_d0",
			"tsin_b_d1",
			"tsin_b_d2",
			"tsin_b_d3",
			"tsin_b_d4",
			"tsin_b_d5",
			"tsin_b_d6",
			"tsin_b_d7",
			"tsin_b_clk",
			"tsin_b_sop",
			"tsin_b_valid";
			function = "tsin";
		};
	};

	dvb_ci_bus_pins_all: dvb_ci_bus_pins_all {
		mux {
			groups = "cicam_a0", "cicam_a1",
			"cicam_a2_c0", "cicam_a3_c1", "cicam_a4_c2",
			"cicam_a5_c3", "cicam_a6_c4", "cicam_a7_c5",
			"cicam_a8_c6", "cicam_a9_c7", "cicam_a10_c8",
			"cicam_a11_c9",
			"cicam_data0", "cicam_data1", "cicam_data2",
			"cicam_data3", "cicam_data4", "cicam_data5",
			"cicam_data6", "cicam_data7",
			"cicam_cen", "cicam_oen", "cicam_wen", "cicam_iordn",
			"cicam_iowrn", "cicam_reset";
			function = "cicam";
		};
	};

	dvb_ci_bus_pins: dvb_ci_bus_pins {
		mux {
			groups = "cicam_a0", "cicam_a1",
			"cicam_data0", "cicam_data1",
			"cicam_data2", "cicam_data3",
			"cicam_data4", "cicam_data5",
			"cicam_data6", "cicam_data7",
			"cicam_cen", "cicam_oen",
			"cicam_wen", "cicam_iordn",
			"cicam_iowrn",
			"cicam_reset";
			function = "cicam";
		};
	};
	ci_ts_pins: ci_ts_pins {
		mux {
			groups = "tsout_sop",
			"tsout_valid",
			"tsout_d0",
			"tsout_d1",
			"tsout_d2",
			"tsout_d3",
			"tsout_d4",
			"tsout_d5",
			"tsout_d6",
			"tsout_d7";
			function = "tsout";
		};
	};
	ci_addr_pins: ci_addr_pins {
		mux {
			groups = "cicam_a2_z8",
			"cicam_a3_z9", "cicam_a4_z10",
			"cicam_a5_z11", "cicam_a6_z12",
			"cicam_a7_z13", "cicam_a8_z14",
			"cicam_a9_z15",
			"cicam_a10_z16", "cicam_a11_z17";
			function = "cicam";
		};
	};

	ci_ts_clk_pins: ci_ts_clk_pins {
		mux {
			groups =  "tsout_clk";
			function = "tsout";
		};
	};
	ci_gpio_pins: ci_gpio_pins {
		mux {
			groups =  "GPIOZ_7";
			function = "gpio_periphs";
		};
	};
	diseqc_out: diseqc_out {
		mux {/*only use out, don't support */
			groups = "diseqc_out_z0";
			function = "diseqc_out";
			bias-pull-down;
		};
	};

	spicc0_pins_h: spicc0_pins_h {
		mux {
			groups = "spi_mosi_a_h10",
				 "spi_miso_a_h9",
				 "spi_ss0_a_h8",
				 "spi_clk_a_h11";
			function = "spi";
			drive-strength-microamp = <3000>;
		};
	};

	spicc0_pins_m: spicc0_pins_m {
		mux {
			groups = "spi_mosi_a_m20",
				 "spi_miso_a_m19",
				 "spi_ss0_a_m22",
				 "spi_clk_a_m21";
			function = "spi";
			drive-strength-microamp = <3000>;
		};
	};

	spicc1_pins_c: spicc1_pins_c {
		mux {
			groups = "spi_mosi_b_c1",
				 "spi_miso_b_c0",
				 "spi_ss0_b_c3",
				 "spi_clk_b_c2";
			function = "spi";
			drive-strength-microamp = <3000>;
		};
	};

	spicc1_pins_z: spicc1_pins_z {
		mux {
			groups = "spi_mosi_b_z1",
				 "spi_miso_b_z0",
				 "spi_ss0_b_z3",
				 "spi_clk_b_z2";
			function = "spi";
			drive-strength-microamp = <3000>;
		};
	};

	sd_iso7816_pins:sd_iso7816_pins {
		mux {
			groups = "iso7816_clk_z0",
				"iso7816_data_z1";
			function = "iso7816";
			input-enable;
			bias-pull-down;
		};
	};

	all_nand_pins: all_nand_pins {
	mux {
			groups = "emmc_d0",
				"emmc_d1",
				"emmc_d2",
				"emmc_d3",
				"emmc_d4",
				"emmc_d5",
				"emmc_d6",
				"emmc_d7",
				"nand_ce0",
				"nand_ale",
				"nand_cle",
				"nand_wen_clk",
				"nand_ren_wr";
			function = "nand";
			input-enable;
		};
	};

	nand_cs_pins: nand_cs {
		mux {
			groups = "nand_ce0";
			function = "nand";
		};
	};

	spinf_pins:spinf_pins {
		mux {
			groups = "spinf_mo_d0",
				 "spinf_mi_d1",
				 "spinf_wp_d2",
				 "spinf_hold_d3",
				 "spinf_d4",
				 "spinf_d5",
				 "spinf_d6",
				 "spinf_d7",
				 "spinf_clk",
				 "spinf_cs0";
			function = "spinf";
			drive-strength-microamp = <3000>;
		};
	};
};

&gpu{
	status = "okay";
	reg =   <0xFE400000 0x40000>, /*mali APB bus base address*/
		<0xFE002000 0x02000>; /*reset register*/
		/*<0xFE000000 0x02000>; gpu clk register*/

	interrupts = <0 144 4>, <0 145 4>, <0 146 4>;
	interrupt-names = "GPU", "MMU", "JOB";
	num_of_pp = <2>;
	/*system-coherency = <31>;*/
	clocks = <&clkc CLKID_MALI>;
	clock-names = "gpu_mux";

	/*
	 * Mali clocking is provided by two identical clock paths
	 * MALI_0 and MALI_1 muxed to a single clock by a glitch
	 * free mux to safely change frequency while running.
	 */
	assigned-clocks = <&clkc CLKID_MALI_0_SEL>,
			  <&clkc CLKID_MALI_0>,
			  <&clkc CLKID_MALI>; /* Glitch free mux */
	assigned-clock-parents = <&clkc CLKID_FCLK_DIV5>,
				 <0>, /* Do Nothing */
				 <&clkc CLKID_MALI_0>;
	assigned-clock-rates = <0>, /* Do Nothing */
			       <400000000>,
			       <0>; /* Do Nothing */

	tbl =  <&dvfs250_cfg
		&dvfs400_cfg
		&dvfs500_cfg
		&dvfs666_cfg
		&dvfs800_cfg
		&dvfs800_cfg>;
};

#include "mesont6d_cpufreq.dtsi"
